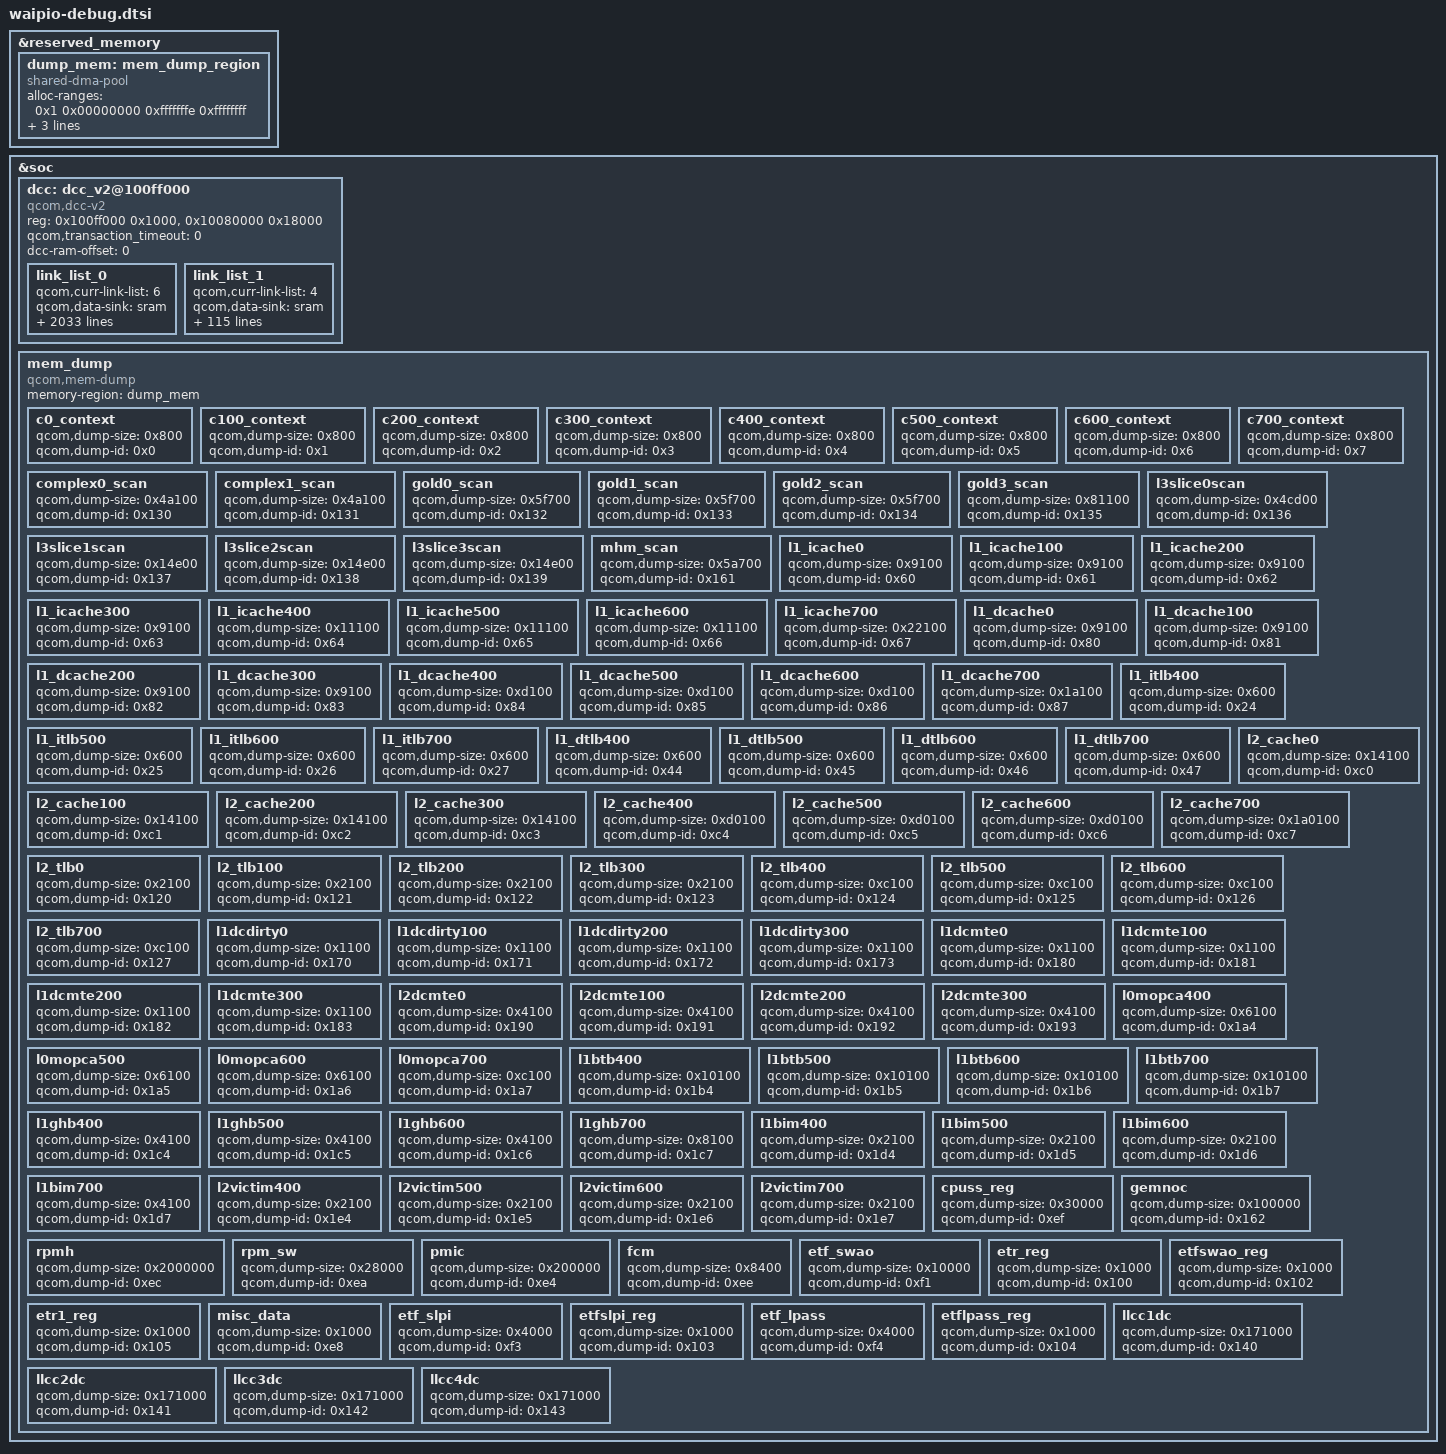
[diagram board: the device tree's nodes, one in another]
#include <dt-bindings/soc/qcom,dcc_v2.h>

&reserved_memory {
	#address-cells = <2>;
	#size-cells = <2>;
	ranges;

	dump_mem: mem_dump_region {
		compatible = "shared-dma-pool";
		alloc-ranges = <0x1 0x00000000 0xfffffffe 0xffffffff>;
		reusable;
		alignment = <0x0 0x400000>;
		size = <0 0x3400000>;
	};
};

&soc {
	dcc: dcc_v2@100ff000 {
		compatible = "qcom,dcc-v2";
		reg = <0x100ff000 0x1000>,
		      <0x10080000 0x18000>;

		qcom,transaction_timeout = <0>;

		reg-names = "dcc-base", "dcc-ram-base";
		dcc-ram-offset = <0>;

		link_list_0 {
			qcom,curr-link-list = <6>;
			qcom,data-sink = "sram";
			qcom,link-list = <DCC_READ 0x1780005c 1 0>,
				<DCC_READ 0x1781005c 1 0>,
				<DCC_READ 0x1782005c 1 0>,
				<DCC_READ 0x1783005c 1 0>,
				<DCC_READ 0x1784005c 1 0>,
				<DCC_READ 0x1785005c 1 0>,
				<DCC_READ 0x1786005c 1 0>,
				<DCC_READ 0x1787005c 1 0>,
				<DCC_READ 0x1740003c 1 0>,
				<DCC_READ 0x17600238 1 0>,
				<DCC_READ 0x17600240 11 0>,
				<DCC_READ 0x17600404 3 0>,
				<DCC_READ 0x1760041c 3 0>,
				<DCC_READ 0x17600434 1 0>,
				<DCC_READ 0x1760043c 1 0>,
				<DCC_READ 0x17600440 1 0>,
				<DCC_READ 0x17400438 1 0>,
				<DCC_READ 0x17600044 1 0>,
				<DCC_READ 0x17600500 1 0>,
				<DCC_READ 0x17600504 5 0>,
				<DCC_READ 0x17900908 1 0>,
				<DCC_READ 0x17900c18 1 0>,
				<DCC_READ 0x17901908 1 0>,
				<DCC_READ 0x17901c18 1 0>,
				<DCC_READ 0x17b90810 1 0>,
				<DCC_READ 0x17b90c50 1 0>,
				<DCC_READ 0x17b90814 1 0>,
				<DCC_READ 0x17b90c54 1 0>,
				<DCC_READ 0x17b90818 1 0>,
				<DCC_READ 0x17b90c58 1 0>,
				<DCC_READ 0x17b93a84 2 0>,
				<DCC_READ 0x17ba0810 1 0>,
				<DCC_READ 0x17ba0c50 1 0>,
				<DCC_READ 0x17ba0814 1 0>,
				<DCC_READ 0x17ba0c54 1 0>,
				<DCC_READ 0x17ba0818 1 0>,
				<DCC_READ 0x17ba0c58 1 0>,
				<DCC_READ 0x17ba3a84 2 0>,
				<DCC_READ 0x17b93500 80 0>,
				<DCC_READ 0x17ba3500 80 0>,
				<DCC_READ 0x17a80000 5 0>,
				<DCC_READ 0x17a8002c 1 0>,
				<DCC_READ 0x17a80038 1 0>,
				<DCC_READ 0x17a82000 5 0>,
				<DCC_READ 0x17a8202c 1 0>,
				<DCC_READ 0x17a82038 1 0>,
				<DCC_READ 0x17a84000 5 0>,
				<DCC_READ 0x17a8402c 1 0>,
				<DCC_READ 0x17a84038 1 0>,
				<DCC_READ 0x17a86000 5 0>,
				<DCC_READ 0x17a8602c 1 0>,
				<DCC_READ 0x17a86038 1 0>,
				<DCC_READ 0x17aa0000 44 0>,
				<DCC_READ 0x17aa00fc 16 0>,
				<DCC_READ 0x17aa0200 2 0>,
				<DCC_READ 0x17aa0300 1 0>,
				<DCC_READ 0x17aa0400 1 0>,
				<DCC_READ 0x17aa0500 1 0>,
				<DCC_READ 0x17aa0600 1 0>,
				<DCC_READ 0x17aa0700 5 0>,
				<DCC_WRITE 0x17a80000 0xf 0>,
				<DCC_READ 0x17a80000 1 0>,
				<DCC_WRITE 0x17a80024 0x0 0>,
				<DCC_READ 0x17a80024 1 0>,
				<DCC_WRITE 0x17a80020 0x0 0>,
				<DCC_READ 0x17a80020 1 0>,
				<DCC_READ 0x17a80038 1 0>,
				<DCC_WRITE 0x17a80020 0x400 0>,
				<DCC_READ 0x17a80020 1 0>,
				<DCC_READ 0x17a80038 1 0>,
				<DCC_WRITE 0x17a80020 0x800 0>,
				<DCC_READ 0x17a80020 1 0>,
				<DCC_READ 0x17a80038 1 0>,
				<DCC_WRITE 0x17a80020 0xc00 0>,
				<DCC_READ 0x17a80020 1 0>,
				<DCC_READ 0x17a80038 1 0>,
				<DCC_WRITE 0x17a80020 0x1000 0>,
				<DCC_READ 0x17a80020 1 0>,
				<DCC_READ 0x17a80038 1 0>,
				<DCC_WRITE 0x17a80020 0x1400 0>,
				<DCC_READ 0x17a80020 1 0>,
				<DCC_READ 0x17a80038 1 0>,
				<DCC_WRITE 0x17a80020 0x1800 0>,
				<DCC_READ 0x17a80020 1 0>,
				<DCC_READ 0x17a80038 1 0>,
				<DCC_WRITE 0x17a80020 0x1c00 0>,
				<DCC_READ 0x17a80020 1 0>,
				<DCC_READ 0x17a80038 1 0>,
				<DCC_WRITE 0x17a80020 0x2000 0>,
				<DCC_READ 0x17a80020 1 0>,
				<DCC_READ 0x17a80038 1 0>,
				<DCC_WRITE 0x17a80020 0x2400 0>,
				<DCC_READ 0x17a80020 1 0>,
				<DCC_READ 0x17a80038 1 0>,
				<DCC_WRITE 0x17a80020 0x2800 0>,
				<DCC_READ 0x17a80020 1 0>,
				<DCC_READ 0x17a80038 1 0>,
				<DCC_WRITE 0x17a80020 0x2c00 0>,
				<DCC_READ 0x17a80020 1 0>,
				<DCC_READ 0x17a80038 1 0>,
				<DCC_WRITE 0x17a80020 0x3000 0>,
				<DCC_READ 0x17a80020 1 0>,
				<DCC_READ 0x17a80038 1 0>,
				<DCC_WRITE 0x17a80020 0x3400 0>,
				<DCC_READ 0x17a80020 1 0>,
				<DCC_READ 0x17a80038 1 0>,
				<DCC_WRITE 0x17a80020 0x3800 0>,
				<DCC_READ 0x17a80020 1 0>,
				<DCC_READ 0x17a80038 1 0>,
				<DCC_WRITE 0x17a80020 0x3c00 0>,
				<DCC_READ 0x17a80020 1 0>,
				<DCC_READ 0x17a80038 1 0>,
				<DCC_WRITE 0x17a80024 0x40000 0>,
				<DCC_READ 0x17a80024 1 0>,
				<DCC_WRITE 0x17a80020 0x0 0>,
				<DCC_READ 0x17a80020 1 0>,
				<DCC_READ 0x17a80038 1 0>,
				<DCC_WRITE 0x17a80020 0x400 0>,
				<DCC_READ 0x17a80020 1 0>,
				<DCC_READ 0x17a80038 1 0>,
				<DCC_WRITE 0x17a80020 0x8000 0>,
				<DCC_READ 0x17a80020 1 0>,
				<DCC_LOOP 32 0 0>,
				<DCC_READ 0x17a80038 1 0>,
				<DCC_LOOP 1 0 0>,
				<DCC_WRITE 0x17a82000 0xf 0>,
				<DCC_READ 0x17a82000 1 0>,
				<DCC_WRITE 0x17a82024 0x0 0>,
				<DCC_READ 0x17a82024 1 0>,
				<DCC_WRITE 0x17a82020 0x0 0>,
				<DCC_READ 0x17a82020 1 0>,
				<DCC_READ 0x17a82038 1 0>,
				<DCC_WRITE 0x17a82020 0x400 0>,
				<DCC_READ 0x17a82020 1 0>,
				<DCC_READ 0x17a82038 1 0>,
				<DCC_WRITE 0x17a82020 0x800 0>,
				<DCC_READ 0x17a82020 1 0>,
				<DCC_READ 0x17a82038 1 0>,
				<DCC_WRITE 0x17a82020 0xc00 0>,
				<DCC_READ 0x17a82020 1 0>,
				<DCC_READ 0x17a82038 1 0>,
				<DCC_WRITE 0x17a82020 0x1000 0>,
				<DCC_READ 0x17a82020 1 0>,
				<DCC_READ 0x17a82038 1 0>,
				<DCC_WRITE 0x17a82020 0x1400 0>,
				<DCC_READ 0x17a82020 1 0>,
				<DCC_READ 0x17a82038 1 0>,
				<DCC_WRITE 0x17a82020 0x1800 0>,
				<DCC_READ 0x17a82020 1 0>,
				<DCC_READ 0x17a82038 1 0>,
				<DCC_WRITE 0x17a82020 0x1c00 0>,
				<DCC_READ 0x17a82020 1 0>,
				<DCC_READ 0x17a82038 1 0>,
				<DCC_WRITE 0x17a82020 0x2000 0>,
				<DCC_READ 0x17a82020 1 0>,
				<DCC_READ 0x17a82038 1 0>,
				<DCC_WRITE 0x17a82020 0x2400 0>,
				<DCC_READ 0x17a82020 1 0>,
				<DCC_READ 0x17a82038 1 0>,
				<DCC_WRITE 0x17a82020 0x2800 0>,
				<DCC_READ 0x17a82020 1 0>,
				<DCC_READ 0x17a82038 1 0>,
				<DCC_WRITE 0x17a82020 0x2c00 0>,
				<DCC_READ 0x17a82020 1 0>,
				<DCC_READ 0x17a82038 1 0>,
				<DCC_WRITE 0x17a82020 0x3000 0>,
				<DCC_READ 0x17a82020 1 0>,
				<DCC_READ 0x17a82038 1 0>,
				<DCC_WRITE 0x17a82020 0x3400 0>,
				<DCC_READ 0x17a82020 1 0>,
				<DCC_READ 0x17a82038 1 0>,
				<DCC_WRITE 0x17a82020 0x3800 0>,
				<DCC_READ 0x17a82020 1 0>,
				<DCC_READ 0x17a82038 1 0>,
				<DCC_WRITE 0x17a82020 0x3c00 0>,
				<DCC_READ 0x17a82020 1 0>,
				<DCC_READ 0x17a82038 1 0>,
				<DCC_WRITE 0x17a82024 0x40000 0>,
				<DCC_READ 0x17a82024 1 0>,
				<DCC_WRITE 0x17a82020 0x0 0>,
				<DCC_READ 0x17a82020 1 0>,
				<DCC_READ 0x17a82038 1 0>,
				<DCC_WRITE 0x17a82020 0x400 0>,
				<DCC_READ 0x17a82020 1 0>,
				<DCC_READ 0x17a82038 1 0>,
				<DCC_WRITE 0x17a82020 0x8000 0>,
				<DCC_READ 0x17a82020 1 0>,
				<DCC_LOOP 32 0 0>,
				<DCC_READ 0x17a82038 1 0>,
				<DCC_LOOP 1 0 0>,
				<DCC_WRITE 0x17a84000 0xf 0>,
				<DCC_READ 0x17a84000 1 0>,
				<DCC_WRITE 0x17a84024 0x0 0>,
				<DCC_READ 0x17a84024 1 0>,
				<DCC_WRITE 0x17a84020 0x0 0>,
				<DCC_READ 0x17a84020 1 0>,
				<DCC_READ 0x17a84038 1 0>,
				<DCC_WRITE 0x17a84020 0x400 0>,
				<DCC_READ 0x17a84020 1 0>,
				<DCC_READ 0x17a84038 1 0>,
				<DCC_WRITE 0x17a84020 0x800 0>,
				<DCC_READ 0x17a84020 1 0>,
				<DCC_READ 0x17a84038 1 0>,
				<DCC_WRITE 0x17a84020 0xc00 0>,
				<DCC_READ 0x17a84020 1 0>,
				<DCC_READ 0x17a84038 1 0>,
				<DCC_WRITE 0x17a84020 0x1000 0>,
				<DCC_READ 0x17a84020 1 0>,
				<DCC_READ 0x17a84038 1 0>,
				<DCC_WRITE 0x17a84020 0x1400 0>,
				<DCC_READ 0x17a84020 1 0>,
				<DCC_READ 0x17a84038 1 0>,
				<DCC_WRITE 0x17a84020 0x1800 0>,
				<DCC_READ 0x17a84020 1 0>,
				<DCC_READ 0x17a84038 1 0>,
				<DCC_WRITE 0x17a84020 0x1c00 0>,
				<DCC_READ 0x17a84020 1 0>,
				<DCC_READ 0x17a84038 1 0>,
				<DCC_WRITE 0x17a84020 0x2000 0>,
				<DCC_READ 0x17a84020 1 0>,
				<DCC_READ 0x17a84038 1 0>,
				<DCC_WRITE 0x17a84020 0x2400 0>,
				<DCC_READ 0x17a84020 1 0>,
				<DCC_READ 0x17a84038 1 0>,
				<DCC_WRITE 0x17a84020 0x2800 0>,
				<DCC_READ 0x17a84020 1 0>,
				<DCC_READ 0x17a84038 1 0>,
				<DCC_WRITE 0x17a84020 0x2c00 0>,
				<DCC_READ 0x17a84020 1 0>,
				<DCC_READ 0x17a84038 1 0>,
				<DCC_WRITE 0x17a84020 0x3000 0>,
				<DCC_READ 0x17a84020 1 0>,
				<DCC_READ 0x17a84038 1 0>,
				<DCC_WRITE 0x17a84020 0x3400 0>,
				<DCC_READ 0x17a84020 1 0>,
				<DCC_READ 0x17a84038 1 0>,
				<DCC_WRITE 0x17a84020 0x3800 0>,
				<DCC_READ 0x17a84020 1 0>,
				<DCC_READ 0x17a84038 1 0>,
				<DCC_WRITE 0x17a84020 0x3c00 0>,
				<DCC_READ 0x17a84020 1 0>,
				<DCC_READ 0x17a84038 1 0>,
				<DCC_WRITE 0x17a84024 0x40000 0>,
				<DCC_READ 0x17a84024 1 0>,
				<DCC_WRITE 0x17a84020 0x0 0>,
				<DCC_READ 0x17a84020 1 0>,
				<DCC_READ 0x17a84038 1 0>,
				<DCC_WRITE 0x17a84020 0x400 0>,
				<DCC_READ 0x17a84020 1 0>,
				<DCC_READ 0x17a84038 1 0>,
				<DCC_WRITE 0x17a84020 0x8000 0>,
				<DCC_READ 0x17a84020 1 0>,
				<DCC_LOOP 32 0 0>,
				<DCC_READ 0x17a84038 1 0>,
				<DCC_LOOP 1 0 0>,
				<DCC_WRITE 0x17a86000 0xf 0>,
				<DCC_READ 0x17a86000 1 0>,
				<DCC_WRITE 0x17a86024 0x0 0>,
				<DCC_READ 0x17a86024 1 0>,
				<DCC_WRITE 0x17a86020 0x0 0>,
				<DCC_READ 0x17a86020 1 0>,
				<DCC_READ 0x17a86038 1 0>,
				<DCC_WRITE 0x17a86020 0x400 0>,
				<DCC_READ 0x17a86020 1 0>,
				<DCC_READ 0x17a86038 1 0>,
				<DCC_WRITE 0x17a86020 0x800 0>,
				<DCC_READ 0x17a86020 1 0>,
				<DCC_READ 0x17a86038 1 0>,
				<DCC_WRITE 0x17a86020 0xc00 0>,
				<DCC_READ 0x17a86020 1 0>,
				<DCC_READ 0x17a86038 1 0>,
				<DCC_WRITE 0x17a86020 0x1000 0>,
				<DCC_READ 0x17a86020 1 0>,
				<DCC_READ 0x17a86038 1 0>,
				<DCC_WRITE 0x17a86020 0x1400 0>,
				<DCC_READ 0x17a86020 1 0>,
				<DCC_READ 0x17a86038 1 0>,
				<DCC_WRITE 0x17a86020 0x1800 0>,
				<DCC_READ 0x17a86020 1 0>,
				<DCC_READ 0x17a86038 1 0>,
				<DCC_WRITE 0x17a86020 0x1c00 0>,
				<DCC_READ 0x17a86020 1 0>,
				<DCC_READ 0x17a86038 1 0>,
				<DCC_WRITE 0x17a86020 0x2000 0>,
				<DCC_READ 0x17a86020 1 0>,
				<DCC_READ 0x17a86038 1 0>,
				<DCC_WRITE 0x17a86020 0x2400 0>,
				<DCC_READ 0x17a86020 1 0>,
				<DCC_READ 0x17a86038 1 0>,
				<DCC_WRITE 0x17a86020 0x2800 0>,
				<DCC_READ 0x17a86020 1 0>,
				<DCC_READ 0x17a86038 1 0>,
				<DCC_WRITE 0x17a86020 0x2c00 0>,
				<DCC_READ 0x17a86020 1 0>,
				<DCC_READ 0x17a86038 1 0>,
				<DCC_WRITE 0x17a86020 0x3000 0>,
				<DCC_READ 0x17a86020 1 0>,
				<DCC_READ 0x17a86038 1 0>,
				<DCC_WRITE 0x17a86020 0x3400 0>,
				<DCC_READ 0x17a86020 1 0>,
				<DCC_READ 0x17a86038 1 0>,
				<DCC_WRITE 0x17a86020 0x3800 0>,
				<DCC_READ 0x17a86020 1 0>,
				<DCC_READ 0x17a86038 1 0>,
				<DCC_WRITE 0x17a86020 0x3c00 0>,
				<DCC_READ 0x17a86020 1 0>,
				<DCC_READ 0x17a86038 1 0>,
				<DCC_WRITE 0x17a86024 0x40000 0>,
				<DCC_READ 0x17a86024 1 0>,
				<DCC_WRITE 0x17a86020 0x0 0>,
				<DCC_READ 0x17a86020 1 0>,
				<DCC_READ 0x17a86038 1 0>,
				<DCC_WRITE 0x17a86020 0x400 0>,
				<DCC_READ 0x17a86020 1 0>,
				<DCC_READ 0x17a86038 1 0>,
				<DCC_WRITE 0x17a86020 0x8000 0>,
				<DCC_READ 0x17a86020 1 0>,
				<DCC_LOOP 32 0 0>,
				<DCC_READ 0x17a86038 1 0>,
				<DCC_LOOP 1 0 0>,
				<DCC_READ 0x0c201244 1 0>,
				<DCC_READ 0x0c202244 1 0>,
				<DCC_READ 0x17b00000 1 0>,
				<DCC_READ 0x17a9208c 1 0>,
				<DCC_WRITE 0x17a9209c 0x78 0>,
				<DCC_WRITE 0x17a9209c 0x0  0>,
				<DCC_WRITE 0x17a92048 0x1  0>,
				<DCC_WRITE 0x17a92090 0x0  0>,
				<DCC_WRITE 0x17a92090 0x25 0>,
				<DCC_READ 0x17a92098 1 0>,
				<DCC_WRITE 0x17a92048 0x1d 0>,
				<DCC_WRITE 0x17a92090 0x0  0>,
				<DCC_WRITE 0x17a92090 0x25 0>,
				<DCC_READ 0x17a92098 1 0>,
				<DCC_READ 0x17a9608c 1 0>,
				<DCC_WRITE 0x17a9609c 0x78 0>,
				<DCC_WRITE 0x17a9609c 0x0  0>,
				<DCC_WRITE 0x17a96048 0x1  0>,
				<DCC_WRITE 0x17a96090 0x0  0>,
				<DCC_WRITE 0x17a96090 0x25 0>,
				<DCC_READ 0x17a96098 1 0>,
				<DCC_WRITE 0x17a96048 0x1d 0>,
				<DCC_WRITE 0x17a96090 0x0  0>,
				<DCC_WRITE 0x17a96090 0x25 0>,
				<DCC_READ 0x17a96098 1 0>,
				<DCC_READ 0x221c21c4 1 0>,
				<DCC_READ 0x01fc8000 1 0>,
				<DCC_READ 0x17400038 1 0>,
				<DCC_READ 0x17d91020 1 0>,
				<DCC_READ 0x17d92020 1 0>,
				<DCC_READ 0x17d93020 1 0>,
				<DCC_READ 0x17d90020 1 0>,
				<DCC_READ 0x17d9134c 1 0>,
				<DCC_READ 0x17d9234c 1 0>,
				<DCC_READ 0x17d9334c 1 0>,
				<DCC_READ 0x17d9034c 1 0>,
				<DCC_READ 0x17d91300 1 0>,
				<DCC_READ 0x17d92300 1 0>,
				<DCC_READ 0x17d93300 1 0>,
				<DCC_READ 0x17d90300 1 0>,
				<DCC_READ 0x19181040 1 0>,
				<DCC_READ 0x19181048 1 0>,
				<DCC_READ 0x19180010 1 0>,
				<DCC_READ 0x19180020 6 0>,
				<DCC_READ 0x19180410 1 0>,
				<DCC_READ 0x19180420 6 0>,
				<DCC_READ 0x19100010 1 0>,
				<DCC_READ 0x19100020 6 0>,
				<DCC_READ 0x19140010 1 0>,
				<DCC_READ 0x19140020 6 0>,
				<DCC_READ 0x19100410 1 0>,
				<DCC_READ 0x19100420 6 0>,
				<DCC_READ 0x19140410 1 0>,
				<DCC_READ 0x19140420 6 0>,
				<DCC_READ 0x19187810 1 0>,
				<DCC_READ 0x19187838 1 0>,
				<DCC_READ 0x19187830 2 0>,
				<DCC_READ 0x19187830 2 0>,
				<DCC_READ 0x19187830 2 0>,
				<DCC_READ 0x19187830 2 0>,
				<DCC_READ 0x19187838 1 0>,
				<DCC_READ 0x19187830 2 0>,
				<DCC_READ 0x19187830 2 0>,
				<DCC_READ 0x19187830 2 0>,
				<DCC_READ 0x19187830 2 0>,
				<DCC_READ 0x19187838 1 0>,
				<DCC_READ 0x19187830 2 0>,
				<DCC_READ 0x19187830 2 0>,
				<DCC_READ 0x19187830 2 0>,
				<DCC_READ 0x19187830 2 0>,
				<DCC_READ 0x19187838 1 0>,
				<DCC_READ 0x19187830 2 0>,
				<DCC_READ 0x19187830 2 0>,
				<DCC_READ 0x19187830 2 0>,
				<DCC_READ 0x19187830 2 0>,
				<DCC_READ 0x19187808 2 0>,
				<DCC_READ 0x19187c10 1 0>,
				<DCC_READ 0x19187c38 1 0>,
				<DCC_READ 0x19187c30 2 0>,
				<DCC_READ 0x19187c30 2 0>,
				<DCC_READ 0x19187c30 2 0>,
				<DCC_READ 0x19187c30 2 0>,
				<DCC_READ 0x19187c38 1 0>,
				<DCC_READ 0x19187c30 2 0>,
				<DCC_READ 0x19187c30 2 0>,
				<DCC_READ 0x19187c30 2 0>,
				<DCC_READ 0x19187c30 2 0>,
				<DCC_READ 0x19187c38 1 0>,
				<DCC_READ 0x19187c30 2 0>,
				<DCC_READ 0x19187c30 2 0>,
				<DCC_READ 0x19187c30 2 0>,
				<DCC_READ 0x19187c30 2 0>,
				<DCC_READ 0x19187c38 1 0>,
				<DCC_READ 0x19187c30 2 0>,
				<DCC_READ 0x19187c30 2 0>,
				<DCC_READ 0x19187c30 2 0>,
				<DCC_READ 0x19187c30 2 0>,
				<DCC_READ 0x19187c08 2 0>,
				<DCC_READ 0x19109010 1 0>,
				<DCC_READ 0x19109038 1 0>,
				<DCC_READ 0x19109030 2 0>,
				<DCC_READ 0x19109030 2 0>,
				<DCC_READ 0x19109030 2 0>,
				<DCC_READ 0x19109030 2 0>,
				<DCC_READ 0x19109038 1 0>,
				<DCC_READ 0x19109030 2 0>,
				<DCC_READ 0x19109030 2 0>,
				<DCC_READ 0x19109030 2 0>,
				<DCC_READ 0x19109030 2 0>,
				<DCC_READ 0x19109038 1 0>,
				<DCC_READ 0x19109030 2 0>,
				<DCC_READ 0x19109030 2 0>,
				<DCC_READ 0x19109030 2 0>,
				<DCC_READ 0x19109030 2 0>,
				<DCC_READ 0x19109038 1 0>,
				<DCC_READ 0x19109030 2 0>,
				<DCC_READ 0x19109030 2 0>,
				<DCC_READ 0x19109030 2 0>,
				<DCC_READ 0x19109030 2 0>,
				<DCC_READ 0x19109008 2 0>,
				<DCC_READ 0x19149010 1 0>,
				<DCC_READ 0x19149038 1 0>,
				<DCC_READ 0x19149030 2 0>,
				<DCC_READ 0x19149030 2 0>,
				<DCC_READ 0x19149030 2 0>,
				<DCC_READ 0x19149030 2 0>,
				<DCC_READ 0x19149038 1 0>,
				<DCC_READ 0x19149030 2 0>,
				<DCC_READ 0x19149030 2 0>,
				<DCC_READ 0x19149030 2 0>,
				<DCC_READ 0x19149030 2 0>,
				<DCC_READ 0x19149038 1 0>,
				<DCC_READ 0x19149030 2 0>,
				<DCC_READ 0x19149030 2 0>,
				<DCC_READ 0x19149030 2 0>,
				<DCC_READ 0x19149030 2 0>,
				<DCC_READ 0x19149038 1 0>,
				<DCC_READ 0x19149030 2 0>,
				<DCC_READ 0x19149030 2 0>,
				<DCC_READ 0x19149030 2 0>,
				<DCC_READ 0x19149030 2 0>,
				<DCC_READ 0x19149008 2 0>,
				<DCC_READ 0x19109410 1 0>,
				<DCC_READ 0x19109438 1 0>,
				<DCC_READ 0x19109430 2 0>,
				<DCC_READ 0x19109430 2 0>,
				<DCC_READ 0x19109430 2 0>,
				<DCC_READ 0x19109430 2 0>,
				<DCC_READ 0x19109438 1 0>,
				<DCC_READ 0x19109430 2 0>,
				<DCC_READ 0x19109430 2 0>,
				<DCC_READ 0x19109430 2 0>,
				<DCC_READ 0x19109430 2 0>,
				<DCC_READ 0x19109438 1 0>,
				<DCC_READ 0x19109430 2 0>,
				<DCC_READ 0x19109430 2 0>,
				<DCC_READ 0x19109430 2 0>,
				<DCC_READ 0x19109430 2 0>,
				<DCC_READ 0x19109438 1 0>,
				<DCC_READ 0x19109430 2 0>,
				<DCC_READ 0x19109430 2 0>,
				<DCC_READ 0x19109430 2 0>,
				<DCC_READ 0x19109430 2 0>,
				<DCC_READ 0x19109408 2 0>,
				<DCC_READ 0x19149410 1 0>,
				<DCC_READ 0x19149438 1 0>,
				<DCC_READ 0x19149430 2 0>,
				<DCC_READ 0x19149430 2 0>,
				<DCC_READ 0x19149430 2 0>,
				<DCC_READ 0x19149430 2 0>,
				<DCC_READ 0x19149438 1 0>,
				<DCC_READ 0x19149430 2 0>,
				<DCC_READ 0x19149430 2 0>,
				<DCC_READ 0x19149430 2 0>,
				<DCC_READ 0x19149430 2 0>,
				<DCC_READ 0x19149438 1 0>,
				<DCC_READ 0x19149430 2 0>,
				<DCC_READ 0x19149430 2 0>,
				<DCC_READ 0x19149430 2 0>,
				<DCC_READ 0x19149430 2 0>,
				<DCC_READ 0x19149438 1 0>,
				<DCC_READ 0x19149430 2 0>,
				<DCC_READ 0x19149430 2 0>,
				<DCC_READ 0x19149430 2 0>,
				<DCC_READ 0x19149430 2 0>,
				<DCC_READ 0x19149408 2 0>,
				<DCC_READ 0x1918f498 1 0>,
				<DCC_READ 0x1918f488 1 0>,
				<DCC_READ 0x1918f490 2 0>,
				<DCC_READ 0x1918f490 2 0>,
				<DCC_READ 0x1918f490 2 0>,
				<DCC_READ 0x1918f490 2 0>,
				<DCC_READ 0x1918f490 2 0>,
				<DCC_READ 0x1918f490 2 0>,
				<DCC_READ 0x1918f490 2 0>,
				<DCC_READ 0x1918f490 2 0>,
				<DCC_READ 0x1918f490 2 0>,
				<DCC_READ 0x1914c098 1 0>,
				<DCC_READ 0x1914c088 1 0>,
				<DCC_READ 0x1914c090 2 0>,
				<DCC_READ 0x1914c090 2 0>,
				<DCC_READ 0x1914c090 2 0>,
				<DCC_READ 0x1914c090 2 0>,
				<DCC_READ 0x1914c090 2 0>,
				<DCC_READ 0x1910c098 1 0>,
				<DCC_READ 0x1910c088 1 0>,
				<DCC_READ 0x1910c090 2 0>,
				<DCC_READ 0x1910c090 2 0>,
				<DCC_READ 0x1910c090 2 0>,
				<DCC_READ 0x1910c090 2 0>,
				<DCC_READ 0x1910c090 2 0>,
				<DCC_READ 0x1918f418 1 0>,
				<DCC_READ 0x1918f408 1 0>,
				<DCC_READ 0x1918f410 2 0>,
				<DCC_READ 0x1918f410 2 0>,
				<DCC_READ 0x1914c018 1 0>,
				<DCC_READ 0x1914c008 1 0>,
				<DCC_READ 0x1914c010 2 0>,
				<DCC_READ 0x1914c010 2 0>,
				<DCC_READ 0x1910c018 1 0>,
				<DCC_READ 0x1910c008 1 0>,
				<DCC_READ 0x1910c010 2 0>,
				<DCC_READ 0x1910c010 2 0>,
				<DCC_READ 0x03d0201c 1 0>,
				<DCC_READ 0x03d00000 1 0>,
				<DCC_READ 0x03d00008 1 0>,
				<DCC_READ 0x03d00044 1 0>,
				<DCC_READ 0x03d00058 1 0>,
				<DCC_READ 0x03d0005c 1 0>,
				<DCC_READ 0x03d00060 1 0>,
				<DCC_READ 0x03d00064 1 0>,
				<DCC_READ 0x03d00068 1 0>,
				<DCC_READ 0x03d0006c 1 0>,
				<DCC_READ 0x03d0007c 1 0>,
				<DCC_READ 0x03d00080 1 0>,
				<DCC_READ 0x03d00084 1 0>,
				<DCC_READ 0x03d00088 1 0>,
				<DCC_READ 0x03d0008c 1 0>,
				<DCC_READ 0x03d00090 1 0>,
				<DCC_READ 0x03d00094 1 0>,
				<DCC_READ 0x03d00098 1 0>,
				<DCC_READ 0x03d0009c 1 0>,
				<DCC_READ 0x03d000a0 1 0>,
				<DCC_READ 0x03d000a4 1 0>,
				<DCC_READ 0x03d000a8 1 0>,
				<DCC_READ 0x03d000ac 1 0>,
				<DCC_READ 0x03d000b0 1 0>,
				<DCC_READ 0x03d000b4 1 0>,
				<DCC_READ 0x03d000b8 1 0>,
				<DCC_READ 0x03d000bc 1 0>,
				<DCC_READ 0x03d000c0 1 0>,
				<DCC_READ 0x03d000c4 1 0>,
				<DCC_READ 0x03d000c8 1 0>,
				<DCC_READ 0x03d000e0 1 0>,
				<DCC_READ 0x03d000e4 1 0>,
				<DCC_READ 0x03d000e8 1 0>,
				<DCC_READ 0x03d000ec 1 0>,
				<DCC_READ 0x03d000f0 1 0>,
				<DCC_READ 0x03d00108 1 0>,
				<DCC_READ 0x03d00110 1 0>,
				<DCC_READ 0x03d0011c 1 0>,
				<DCC_READ 0x03d00124 1 0>,
				<DCC_READ 0x03d00128 1 0>,
				<DCC_READ 0x03d00130 1 0>,
				<DCC_READ 0x03d00140 1 0>,
				<DCC_READ 0x03d00158 1 0>,
				<DCC_READ 0x03d001cc 1 0>,
				<DCC_READ 0x03d001d0 1 0>,
				<DCC_READ 0x03d001d4 1 0>,
				<DCC_READ 0x03d002b4 1 0>,
				<DCC_READ 0x03d002b8 1 0>,
				<DCC_READ 0x03d002c0 1 0>,
				<DCC_READ 0x03d002d0 1 0>,
				<DCC_READ 0x03d002e0 1 0>,
				<DCC_READ 0x03d002f0 1 0>,
				<DCC_READ 0x03d00300 1 0>,
				<DCC_READ 0x03d00310 1 0>,
				<DCC_READ 0x03d00320 1 0>,
				<DCC_READ 0x03d00330 1 0>,
				<DCC_READ 0x03d00340 1 0>,
				<DCC_READ 0x03d00350 1 0>,
				<DCC_READ 0x03d00360 1 0>,
				<DCC_READ 0x03d00370 1 0>,
				<DCC_READ 0x03d00380 1 0>,
				<DCC_READ 0x03d00390 1 0>,
				<DCC_READ 0x03d003a0 1 0>,
				<DCC_READ 0x03d003b0 1 0>,
				<DCC_READ 0x03d003c0 1 0>,
				<DCC_READ 0x03d003d0 1 0>,
				<DCC_READ 0x03d003e0 1 0>,
				<DCC_READ 0x03d00400 1 0>,
				<DCC_READ 0x03d00410 1 0>,
				<DCC_READ 0x03d00414 1 0>,
				<DCC_READ 0x03d00418 1 0>,
				<DCC_READ 0x03d0041c 1 0>,
				<DCC_READ 0x03d00420 1 0>,
				<DCC_READ 0x03d00424 1 0>,
				<DCC_READ 0x03d00428 1 0>,
				<DCC_READ 0x03d0042c 1 0>,
				<DCC_READ 0x03d0043c 1 0>,
				<DCC_READ 0x03d00440 1 0>,
				<DCC_READ 0x03d00444 1 0>,
				<DCC_READ 0x03d00448 1 0>,
				<DCC_READ 0x03d0044c 1 0>,
				<DCC_READ 0x03d00450 1 0>,
				<DCC_READ 0x03d00454 1 0>,
				<DCC_READ 0x03d00458 1 0>,
				<DCC_READ 0x03d0045c 1 0>,
				<DCC_READ 0x03d00460 1 0>,
				<DCC_READ 0x03d00464 1 0>,
				<DCC_READ 0x03d00468 1 0>,
				<DCC_READ 0x03d0046c 1 0>,
				<DCC_READ 0x03d00470 1 0>,
				<DCC_READ 0x03d00474 1 0>,
				<DCC_READ 0x03d004bc 1 0>,
				<DCC_READ 0x03d00800 1 0>,
				<DCC_READ 0x03d00804 1 0>,
				<DCC_READ 0x03d00808 1 0>,
				<DCC_READ 0x03d0080c 1 0>,
				<DCC_READ 0x03d00810 1 0>,
				<DCC_READ 0x03d00814 1 0>,
				<DCC_READ 0x03d00818 1 0>,
				<DCC_READ 0x03d0081c 1 0>,
				<DCC_READ 0x03d00820 1 0>,
				<DCC_READ 0x03d00824 1 0>,
				<DCC_READ 0x03d00828 1 0>,
				<DCC_READ 0x03d0082c 1 0>,
				<DCC_READ 0x03d00830 1 0>,
				<DCC_READ 0x03d00834 1 0>,
				<DCC_READ 0x03d00840 1 0>,
				<DCC_READ 0x03d00844 1 0>,
				<DCC_READ 0x03d00848 1 0>,
				<DCC_READ 0x03d0084c 1 0>,
				<DCC_READ 0x03d00854 1 0>,
				<DCC_READ 0x03d00858 1 0>,
				<DCC_READ 0x03d0085c 1 0>,
				<DCC_READ 0x03d00860 1 0>,
				<DCC_READ 0x03d00864 1 0>,
				<DCC_READ 0x03d00868 1 0>,
				<DCC_READ 0x03d0086c 1 0>,
				<DCC_READ 0x03d00870 1 0>,
				<DCC_READ 0x03d00874 1 0>,
				<DCC_READ 0x03d00878 1 0>,
				<DCC_READ 0x03d0087c 1 0>,
				<DCC_READ 0x03d00880 1 0>,
				<DCC_READ 0x03d00884 1 0>,
				<DCC_READ 0x03d00888 1 0>,
				<DCC_READ 0x03d0088c 1 0>,
				<DCC_READ 0x03d00890 1 0>,
				<DCC_READ 0x03d00894 1 0>,
				<DCC_READ 0x03d00898 1 0>,
				<DCC_READ 0x03d0089c 1 0>,
				<DCC_READ 0x03d008a0 1 0>,
				<DCC_READ 0x03d008a4 1 0>,
				<DCC_READ 0x03d008a8 1 0>,
				<DCC_READ 0x03d008ac 1 0>,
				<DCC_READ 0x03d008b0 1 0>,
				<DCC_READ 0x03d008b4 1 0>,
				<DCC_READ 0x03d008b8 1 0>,
				<DCC_READ 0x03d008bc 1 0>,
				<DCC_READ 0x03d008c0 1 0>,
				<DCC_READ 0x03d008c4 1 0>,
				<DCC_READ 0x03d008c8 1 0>,
				<DCC_READ 0x03d008cc 1 0>,
				<DCC_READ 0x03d008d0 1 0>,
				<DCC_READ 0x03d008d4 1 0>,
				<DCC_READ 0x03d008d8 1 0>,
				<DCC_READ 0x03d008dc 1 0>,
				<DCC_READ 0x03d008e0 1 0>,
				<DCC_READ 0x03d008e4 1 0>,
				<DCC_READ 0x03d008e8 1 0>,
				<DCC_READ 0x03d008ec 1 0>,
				<DCC_READ 0x03d008f0 1 0>,
				<DCC_READ 0x03d008f4 1 0>,
				<DCC_READ 0x03d008f8 1 0>,
				<DCC_READ 0x03d008fc 1 0>,
				<DCC_READ 0x03d00900 1 0>,
				<DCC_READ 0x03d00904 1 0>,
				<DCC_READ 0x03d00908 1 0>,
				<DCC_READ 0x03d0090c 1 0>,
				<DCC_READ 0x03d00980 1 0>,
				<DCC_READ 0x03d00984 1 0>,
				<DCC_READ 0x03d00988 1 0>,
				<DCC_READ 0x03d0098c 1 0>,
				<DCC_READ 0x03d00990 1 0>,
				<DCC_READ 0x03d00994 1 0>,
				<DCC_READ 0x03d00998 1 0>,
				<DCC_READ 0x03d0099c 1 0>,
				<DCC_READ 0x03d009a0 1 0>,
				<DCC_READ 0x03d009c8 1 0>,
				<DCC_READ 0x03d009cc 1 0>,
				<DCC_READ 0x03d009d0 1 0>,
				<DCC_READ 0x03d00a04 1 0>,
				<DCC_READ 0x03d00a08 1 0>,
				<DCC_READ 0x03d00a0c 1 0>,
				<DCC_READ 0x03d00a10 1 0>,
				<DCC_READ 0x03d00a14 1 0>,
				<DCC_READ 0x03d00a18 1 0>,
				<DCC_READ 0x03d00a1c 1 0>,
				<DCC_READ 0x03d00a20 1 0>,
				<DCC_READ 0x03d00a24 1 0>,
				<DCC_READ 0x03d00a28 1 0>,
				<DCC_READ 0x03d00a2c 1 0>,
				<DCC_READ 0x03d00a30 1 0>,
				<DCC_READ 0x03d00a34 1 0>,
				<DCC_READ 0x03d01444 1 0>,
				<DCC_READ 0x03d014d4 1 0>,
				<DCC_READ 0x03d014d8 1 0>,
				<DCC_READ 0x03d017ec 1 0>,
				<DCC_READ 0x03d017f0 1 0>,
				<DCC_READ 0x03d017f4 1 0>,
				<DCC_READ 0x03d017f8 1 0>,
				<DCC_READ 0x03d017fc 1 0>,
				<DCC_READ 0x03d99800 1 0>,
				<DCC_READ 0x03d99804 1 0>,
				<DCC_READ 0x03d99808 1 0>,
				<DCC_READ 0x03d9980c 1 0>,
				<DCC_READ 0x03d99810 1 0>,
				<DCC_READ 0x03d99814 1 0>,
				<DCC_READ 0x03d99818 1 0>,
				<DCC_READ 0x03d9981c 1 0>,
				<DCC_READ 0x03d99828 1 0>,
				<DCC_READ 0x03d9983c 1 0>,
				<DCC_READ 0x03d998ac 1 0>,
				<DCC_READ 0x0018101c 1 0>,
				<DCC_READ 0x00181020 1 0>,
				<DCC_READ 0x03d94000 1 0>,
				<DCC_READ 0x03d94004 1 0>,
				<DCC_READ 0x03d95000 1 0>,
				<DCC_READ 0x03d95004 1 0>,
				<DCC_READ 0x03d95008 1 0>,
				<DCC_READ 0x03d9500c 1 0>,
				<DCC_READ 0x03d96000 1 0>,
				<DCC_READ 0x03d96004 1 0>,
				<DCC_READ 0x03d96008 1 0>,
				<DCC_READ 0x03d9600c 1 0>,
				<DCC_READ 0x03d97000 1 0>,
				<DCC_READ 0x03d97004 1 0>,
				<DCC_READ 0x03d97008 1 0>,
				<DCC_READ 0x03d9700c 1 0>,
				<DCC_READ 0x03d98000 1 0>,
				<DCC_READ 0x03d98004 1 0>,
				<DCC_READ 0x03d98008 1 0>,
				<DCC_READ 0x03d9800c 1 0>,
				<DCC_READ 0x03d99000 1 0>,
				<DCC_READ 0x03d99004 1 0>,
				<DCC_READ 0x03d99008 1 0>,
				<DCC_READ 0x03d9900c 1 0>,
				<DCC_READ 0x03d99010 1 0>,
				<DCC_READ 0x03d99014 1 0>,
				<DCC_READ 0x03d99050 1 0>,
				<DCC_READ 0x03d99054 1 0>,
				<DCC_READ 0x03d99058 1 0>,
				<DCC_READ 0x03d9905c 1 0>,
				<DCC_READ 0x03d99060 1 0>,
				<DCC_READ 0x03d99064 1 0>,
				<DCC_READ 0x03d99068 1 0>,
				<DCC_READ 0x03d9906c 1 0>,
				<DCC_READ 0x03d99070 1 0>,
				<DCC_READ 0x03d99074 1 0>,
				<DCC_READ 0x03d990a8 1 0>,
				<DCC_READ 0x03d990ac 1 0>,
				<DCC_READ 0x03d990b8 1 0>,
				<DCC_READ 0x03d990bc 1 0>,
				<DCC_READ 0x03d990c0 1 0>,
				<DCC_READ 0x03d990c8 1 0>,
				<DCC_READ 0x03d99104 1 0>,
				<DCC_READ 0x03d99108 1 0>,
				<DCC_READ 0x03d9910c 1 0>,
				<DCC_READ 0x03d99110 1 0>,
				<DCC_READ 0x03d99114 1 0>,
				<DCC_READ 0x03d99118 1 0>,
				<DCC_READ 0x03d9911c 1 0>,
				<DCC_READ 0x03d99120 1 0>,
				<DCC_READ 0x03d99130 1 0>,
				<DCC_READ 0x03d99134 1 0>,
				<DCC_READ 0x03d9913c 1 0>,
				<DCC_READ 0x03d99140 1 0>,
				<DCC_READ 0x03d99144 1 0>,
				<DCC_READ 0x03d99148 1 0>,
				<DCC_READ 0x03d9914c 1 0>,
				<DCC_READ 0x03d99150 1 0>,
				<DCC_READ 0x03d99154 1 0>,
				<DCC_READ 0x03d99198 1 0>,
				<DCC_READ 0x03d9919c 1 0>,
				<DCC_READ 0x03d991a0 1 0>,
				<DCC_READ 0x03d991e0 1 0>,
				<DCC_READ 0x03d991e4 1 0>,
				<DCC_READ 0x03d991e8 1 0>,
				<DCC_READ 0x03d99224 1 0>,
				<DCC_READ 0x03d99228 1 0>,
				<DCC_READ 0x03d99280 1 0>,
				<DCC_READ 0x03d99284 1 0>,
				<DCC_READ 0x03d99288 1 0>,
				<DCC_READ 0x03d9928c 1 0>,
				<DCC_READ 0x03d992cc 1 0>,
				<DCC_READ 0x03d992d0 1 0>,
				<DCC_READ 0x03d992d4 1 0>,
				<DCC_READ 0x03d99314 1 0>,
				<DCC_READ 0x03d99318 1 0>,
				<DCC_READ 0x03d9931c 1 0>,
				<DCC_READ 0x03d99358 1 0>,
				<DCC_READ 0x03d9935c 1 0>,
				<DCC_READ 0x03d99360 1 0>,
				<DCC_READ 0x03d993a0 1 0>,
				<DCC_READ 0x03d993a4 1 0>,
				<DCC_READ 0x03d993e4 1 0>,
				<DCC_READ 0x03d993e8 1 0>,
				<DCC_READ 0x03d993ec 1 0>,
				<DCC_READ 0x03d993f0 1 0>,
				<DCC_READ 0x03d9942c 1 0>,
				<DCC_READ 0x03d99430 1 0>,
				<DCC_READ 0x03d99470 1 0>,
				<DCC_READ 0x03d99474 1 0>,
				<DCC_READ 0x03d99478 1 0>,
				<DCC_READ 0x03d99500 1 0>,
				<DCC_READ 0x03d99504 1 0>,
				<DCC_READ 0x03d99508 1 0>,
				<DCC_READ 0x03d9950c 1 0>,
				<DCC_READ 0x03d99528 1 0>,
				<DCC_READ 0x03d9952c 1 0>,
				<DCC_READ 0x03d99530 1 0>,
				<DCC_READ 0x03d99534 1 0>,
				<DCC_READ 0x03d99538 1 0>,
				<DCC_READ 0x03d9953c 1 0>,
				<DCC_READ 0x03d99540 1 0>,
				<DCC_READ 0x03d99544 1 0>,
				<DCC_READ 0x03d99548 1 0>,
				<DCC_READ 0x03d9954c 1 0>,
				<DCC_READ 0x03d99550 1 0>,
				<DCC_READ 0x03d99554 1 0>,
				<DCC_READ 0x03d99558 1 0>,
				<DCC_READ 0x03d9955c 1 0>,
				<DCC_READ 0x03d99560 1 0>,
				<DCC_READ 0x03d99564 1 0>,
				<DCC_READ 0x03d99568 1 0>,
				<DCC_READ 0x03d9956c 1 0>,
				<DCC_READ 0x03d99570 1 0>,
				<DCC_READ 0x03d99574 1 0>,
				<DCC_READ 0x03d99578 1 0>,
				<DCC_READ 0x03d9957c 1 0>,
				<DCC_READ 0x03d99580 1 0>,
				<DCC_READ 0x03d99584 1 0>,
				<DCC_READ 0x03d99588 1 0>,
				<DCC_READ 0x03d9958c 1 0>,
				<DCC_READ 0x03d99590 1 0>,
				<DCC_READ 0x03d99594 1 0>,
				<DCC_READ 0x03d99598 1 0>,
				<DCC_READ 0x03d9959c 1 0>,
				<DCC_READ 0x03d995a0 1 0>,
				<DCC_READ 0x03d995a4 1 0>,
				<DCC_READ 0x03d995a8 1 0>,
				<DCC_READ 0x03d995ac 1 0>,
				<DCC_READ 0x03d995b0 1 0>,
				<DCC_READ 0x03d995b4 1 0>,
				<DCC_READ 0x03d995b8 1 0>,
				<DCC_READ 0x03d995bc 1 0>,
				<DCC_READ 0x03d995c0 1 0>,
				<DCC_READ 0x03d3b000 1 0>,
				<DCC_READ 0x03d3b004 1 0>,
				<DCC_READ 0x03d3b014 1 0>,
				<DCC_READ 0x03d3b01c 1 0>,
				<DCC_READ 0x03d3b028 1 0>,
				<DCC_READ 0x03d3b0ac 1 0>,
				<DCC_READ 0x03d3b100 1 0>,
				<DCC_READ 0x03d3b104 1 0>,
				<DCC_READ 0x03d3b114 1 0>,
				<DCC_READ 0x03d3b11c 1 0>,
				<DCC_READ 0x03d3b128 1 0>,
				<DCC_READ 0x03d3b1ac 1 0>,
				<DCC_READ 0x03d90000 1 0>,
				<DCC_READ 0x03d90004 1 0>,
				<DCC_READ 0x03d90008 1 0>,
				<DCC_READ 0x03d9000c 1 0>,
				<DCC_READ 0x03d90010 1 0>,
				<DCC_READ 0x03d90014 1 0>,
				<DCC_READ 0x03d90018 1 0>,
				<DCC_READ 0x03d9001c 1 0>,
				<DCC_READ 0x03d90020 1 0>,
				<DCC_READ 0x03d90024 1 0>,
				<DCC_READ 0x03d90028 1 0>,
				<DCC_READ 0x03d9002c 1 0>,
				<DCC_READ 0x03d90030 1 0>,
				<DCC_READ 0x03d90034 1 0>,
				<DCC_READ 0x03d90038 1 0>,
				<DCC_READ 0x03d91000 1 0>,
				<DCC_READ 0x03d91004 1 0>,
				<DCC_READ 0x03d91008 1 0>,
				<DCC_READ 0x03d9100c 1 0>,
				<DCC_READ 0x03d91010 1 0>,
				<DCC_READ 0x03d91014 1 0>,
				<DCC_READ 0x03d91018 1 0>,
				<DCC_READ 0x03d9101c 1 0>,
				<DCC_READ 0x03d91020 1 0>,
				<DCC_READ 0x03d91024 1 0>,
				<DCC_READ 0x03d91028 1 0>,
				<DCC_READ 0x03d9102c 1 0>,
				<DCC_READ 0x03d91030 1 0>,
				<DCC_READ 0x03d91034 1 0>,
				<DCC_READ 0x03d91038 1 0>,
				<DCC_READ 0x03d50000 1 0>,
				<DCC_READ 0x03d50004 1 0>,
				<DCC_READ 0x03d50008 1 0>,
				<DCC_READ 0x03d5000c 1 0>,
				<DCC_READ 0x03d50010 1 0>,
				<DCC_READ 0x03d50014 1 0>,
				<DCC_READ 0x03d50018 1 0>,
				<DCC_READ 0x03d5001c 1 0>,
				<DCC_READ 0x03d50020 1 0>,
				<DCC_READ 0x03d50024 1 0>,
				<DCC_READ 0x03d50028 1 0>,
				<DCC_READ 0x03d5002c 1 0>,
				<DCC_READ 0x03d50030 1 0>,
				<DCC_READ 0x03d50034 1 0>,
				<DCC_READ 0x03d50038 1 0>,
				<DCC_READ 0x03d5003c 1 0>,
				<DCC_READ 0x03d50040 1 0>,
				<DCC_READ 0x03d50044 1 0>,
				<DCC_READ 0x03d50048 1 0>,
				<DCC_READ 0x03d5004c 1 0>,
				<DCC_READ 0x03d50050 1 0>,
				<DCC_READ 0x03d500d0 1 0>,
				<DCC_READ 0x03d500d8 1 0>,
				<DCC_READ 0x03d50100 1 0>,
				<DCC_READ 0x03d50104 1 0>,
				<DCC_READ 0x03d50108 1 0>,
				<DCC_READ 0x03d50200 1 0>,
				<DCC_READ 0x03d50204 1 0>,
				<DCC_READ 0x03d50208 1 0>,
				<DCC_READ 0x03d5020c 1 0>,
				<DCC_READ 0x03d50210 1 0>,
				<DCC_READ 0x03d50400 1 0>,
				<DCC_READ 0x03d50404 1 0>,
				<DCC_READ 0x03d50408 1 0>,
				<DCC_READ 0x03d50450 1 0>,
				<DCC_READ 0x03d50460 1 0>,
				<DCC_READ 0x03d50464 1 0>,
				<DCC_READ 0x03d50490 1 0>,
				<DCC_READ 0x03d50494 1 0>,
				<DCC_READ 0x03d50498 1 0>,
				<DCC_READ 0x03d5049c 1 0>,
				<DCC_READ 0x03d504a0 1 0>,
				<DCC_READ 0x03d504a4 1 0>,
				<DCC_READ 0x03d504a8 1 0>,
				<DCC_READ 0x03d504ac 1 0>,
				<DCC_READ 0x03d504b0 1 0>,
				<DCC_READ 0x03d504b4 1 0>,
				<DCC_READ 0x03d504b8 1 0>,
				<DCC_READ 0x03d50500 1 0>,
				<DCC_READ 0x03d50600 1 0>,
				<DCC_READ 0x03d50d00 1 0>,
				<DCC_READ 0x03d50d04 1 0>,
				<DCC_READ 0x03d50d10 1 0>,
				<DCC_READ 0x03d50d14 1 0>,
				<DCC_READ 0x03d50d18 1 0>,
				<DCC_READ 0x03d50d1c 1 0>,
				<DCC_READ 0x03d50d30 1 0>,
				<DCC_READ 0x03d50d34 1 0>,
				<DCC_READ 0x03d50d38 1 0>,
				<DCC_READ 0x03d50d3c 1 0>,
				<DCC_READ 0x03d50d40 1 0>,
				<DCC_READ 0x03d53d44 1 0>,
				<DCC_READ 0x03d53d4c 1 0>,
				<DCC_READ 0x03d53d50 1 0>,
				<DCC_READ 0x03d8e100 1 0>,
				<DCC_READ 0x03d8e104 1 0>,
				<DCC_READ 0x03d8ec00 1 0>,
				<DCC_READ 0x03d8ec04 1 0>,
				<DCC_READ 0x03d8ec0c 1 0>,
				<DCC_READ 0x03d8ec14 1 0>,
				<DCC_READ 0x03d8ec18 1 0>,
				<DCC_READ 0x03d8ec1c 1 0>,
				<DCC_READ 0x03d8ec20 1 0>,
				<DCC_READ 0x03d8ec24 1 0>,
				<DCC_READ 0x03d8ec28 1 0>,
				<DCC_READ 0x03d8ec2c 1 0>,
				<DCC_READ 0x03d8ec30 1 0>,
				<DCC_READ 0x03d8ec34 1 0>,
				<DCC_READ 0x03d8ec38 1 0>,
				<DCC_READ 0x03d8ec40 1 0>,
				<DCC_READ 0x03d8ec44 1 0>,
				<DCC_READ 0x03d8ec48 1 0>,
				<DCC_READ 0x03d8ec4c 1 0>,
				<DCC_READ 0x03d8ec54 1 0>,
				<DCC_READ 0x03d8ec58 1 0>,
				<DCC_READ 0x03d8ec80 1 0>,
				<DCC_READ 0x03d8eca0 1 0>,
				<DCC_READ 0x03d8ecc0 1 0>,
				<DCC_READ 0x03d7d000 1 0>,
				<DCC_READ 0x03d7d004 1 0>,
				<DCC_READ 0x03d7d008 1 0>,
				<DCC_READ 0x03d7d00c 1 0>,
				<DCC_READ 0x03d7d010 1 0>,
				<DCC_READ 0x03d7d014 1 0>,
				<DCC_READ 0x03d7d018 1 0>,
				<DCC_READ 0x03d7d01c 1 0>,
				<DCC_READ 0x03d7d020 1 0>,
				<DCC_READ 0x03d7d024 1 0>,
				<DCC_READ 0x03d7d028 1 0>,
				<DCC_READ 0x03d7d02c 1 0>,
				<DCC_READ 0x03d7d030 1 0>,
				<DCC_READ 0x03d7d034 1 0>,
				<DCC_READ 0x03d7d03c 1 0>,
				<DCC_READ 0x03d7d040 1 0>,
				<DCC_READ 0x03d7d044 1 0>,
				<DCC_READ 0x03d7d400 1 0>,
				<DCC_READ 0x03d7d41c 1 0>,
				<DCC_READ 0x03d7d424 1 0>,
				<DCC_READ 0x03d7d428 1 0>,
				<DCC_READ 0x03d7d42c 1 0>,
				<DCC_READ 0x03d7e000 1 0>,
				<DCC_READ 0x03d7e004 1 0>,
				<DCC_READ 0x03d7e008 1 0>,
				<DCC_READ 0x03d7e00c 1 0>,
				<DCC_READ 0x03d7e010 1 0>,
				<DCC_READ 0x03d7e01c 1 0>,
				<DCC_READ 0x03d7e020 1 0>,
				<DCC_READ 0x03d7e02c 1 0>,
				<DCC_READ 0x03d7e030 1 0>,
				<DCC_READ 0x03d7e03c 1 0>,
				<DCC_READ 0x03d7e044 1 0>,
				<DCC_READ 0x03d7e04c 1 0>,
				<DCC_READ 0x03d7e050 1 0>,
				<DCC_READ 0x03d7e054 1 0>,
				<DCC_READ 0x03d7e058 1 0>,
				<DCC_READ 0x03d7e05c 1 0>,
				<DCC_READ 0x03d7e064 1 0>,
				<DCC_READ 0x03d7e068 1 0>,
				<DCC_READ 0x03d7e06c 1 0>,
				<DCC_READ 0x03d7e070 1 0>,
				<DCC_READ 0x03d7e090 1 0>,
				<DCC_READ 0x03d7e094 1 0>,
				<DCC_READ 0x03d7e098 1 0>,
				<DCC_READ 0x03d7e09c 1 0>,
				<DCC_READ 0x03d7e0a0 1 0>,
				<DCC_READ 0x03d7e0a4 1 0>,
				<DCC_READ 0x03d7e0a8 1 0>,
				<DCC_READ 0x03d7e0b4 1 0>,
				<DCC_READ 0x03d7e0b8 1 0>,
				<DCC_READ 0x03d7e0bc 1 0>,
				<DCC_READ 0x03d7e0c0 1 0>,
				<DCC_READ 0x03d7e100 1 0>,
				<DCC_READ 0x03d7e104 1 0>,
				<DCC_READ 0x03d7e108 1 0>,
				<DCC_READ 0x03d7e10c 1 0>,
				<DCC_READ 0x03d7e110 1 0>,
				<DCC_READ 0x03d7e114 1 0>,
				<DCC_READ 0x03d7e118 1 0>,
				<DCC_READ 0x03d7e11c 1 0>,
				<DCC_READ 0x03d7e120 1 0>,
				<DCC_READ 0x03d7e124 1 0>,
				<DCC_READ 0x03d7e128 1 0>,
				<DCC_READ 0x03d7e12c 1 0>,
				<DCC_READ 0x03d7e130 1 0>,
				<DCC_READ 0x03d7e134 1 0>,
				<DCC_READ 0x03d7e138 1 0>,
				<DCC_READ 0x03d7e13c 1 0>,
				<DCC_READ 0x03d7e140 1 0>,
				<DCC_READ 0x03d7e144 1 0>,
				<DCC_READ 0x03d7e148 1 0>,
				<DCC_READ 0x03d7e14c 1 0>,
				<DCC_READ 0x03d7e180 1 0>,
				<DCC_READ 0x03d7e1c0 1 0>,
				<DCC_READ 0x03d7e1c4 1 0>,
				<DCC_READ 0x03d7e1c8 1 0>,
				<DCC_READ 0x03d7e1cc 1 0>,
				<DCC_READ 0x03d7e1d0 1 0>,
				<DCC_READ 0x03d7e1d4 1 0>,
				<DCC_READ 0x03d7e1d8 1 0>,
				<DCC_READ 0x03d7e1dc 1 0>,
				<DCC_READ 0x03d7e1e0 1 0>,
				<DCC_READ 0x03d7e1e4 1 0>,
				<DCC_READ 0x03d7e1fc 1 0>,
				<DCC_READ 0x03d7e220 1 0>,
				<DCC_READ 0x03d7e224 1 0>,
				<DCC_READ 0x03d7e300 1 0>,
				<DCC_READ 0x03d7e304 1 0>,
				<DCC_READ 0x03d7e30c 1 0>,
				<DCC_READ 0x03d7e310 1 0>,
				<DCC_READ 0x03d7e340 1 0>,
				<DCC_READ 0x03d7e3b0 1 0>,
				<DCC_READ 0x03d7e3c0 1 0>,
				<DCC_READ 0x03d7e3c4 1 0>,
				<DCC_READ 0x03d7e440 1 0>,
				<DCC_READ 0x03d7e444 1 0>,
				<DCC_READ 0x03d7e448 1 0>,
				<DCC_READ 0x03d7e44c 1 0>,
				<DCC_READ 0x03d7e450 1 0>,
				<DCC_READ 0x03d7e480 1 0>,
				<DCC_READ 0x03d7e484 1 0>,
				<DCC_READ 0x03d7e490 1 0>,
				<DCC_READ 0x03d7e494 1 0>,
				<DCC_READ 0x03d7e4a0 1 0>,
				<DCC_READ 0x03d7e4a4 1 0>,
				<DCC_READ 0x03d7e4b0 1 0>,
				<DCC_READ 0x03d7e4b4 1 0>,
				<DCC_READ 0x03d7e500 1 0>,
				<DCC_READ 0x03d7e508 1 0>,
				<DCC_READ 0x03d7e50c 1 0>,
				<DCC_READ 0x03d7e510 1 0>,
				<DCC_READ 0x03d7e520 1 0>,
				<DCC_READ 0x03d7e524 1 0>,
				<DCC_READ 0x03d7e528 1 0>,
				<DCC_READ 0x03d7e53c 1 0>,
				<DCC_READ 0x03d7e540 1 0>,
				<DCC_READ 0x03d7e544 1 0>,
				<DCC_READ 0x03d7e560 1 0>,
				<DCC_READ 0x03d7e564 1 0>,
				<DCC_READ 0x03d7e568 1 0>,
				<DCC_READ 0x03d7e574 1 0>,
				<DCC_READ 0x03d7e588 1 0>,
				<DCC_READ 0x03d7e590 1 0>,
				<DCC_READ 0x03d7e594 1 0>,
				<DCC_READ 0x03d7e598 1 0>,
				<DCC_READ 0x03d7e59c 1 0>,
				<DCC_READ 0x03d7e5a0 1 0>,
				<DCC_READ 0x03d7e5a4 1 0>,
				<DCC_READ 0x03d7e5a8 1 0>,
				<DCC_READ 0x03d7e5ac 1 0>,
				<DCC_READ 0x03d7e5c0 1 0>,
				<DCC_READ 0x03d7e5c4 1 0>,
				<DCC_READ 0x03d7e5c8 1 0>,
				<DCC_READ 0x03d7e5cc 1 0>,
				<DCC_READ 0x03d7e5d0 1 0>,
				<DCC_READ 0x03d7e5d4 1 0>,
				<DCC_READ 0x03d7e5d8 1 0>,
				<DCC_READ 0x03d7e5dc 1 0>,
				<DCC_READ 0x03d7e5e0 1 0>,
				<DCC_READ 0x03d7e5e4 1 0>,
				<DCC_READ 0x03d7e600 1 0>,
				<DCC_READ 0x03d7e604 1 0>,
				<DCC_READ 0x03d7e610 1 0>,
				<DCC_READ 0x03d7e614 1 0>,
				<DCC_READ 0x03d7e618 1 0>,
				<DCC_READ 0x03d7e648 1 0>,
				<DCC_READ 0x03d7e64c 1 0>,
				<DCC_READ 0x03d7e658 1 0>,
				<DCC_READ 0x03d7e65c 1 0>,
				<DCC_READ 0x03d7e660 1 0>,
				<DCC_READ 0x03d7e664 1 0>,
				<DCC_READ 0x03d7e668 1 0>,
				<DCC_READ 0x03d7e66c 1 0>,
				<DCC_READ 0x03d7e670 1 0>,
				<DCC_READ 0x03d7e674 1 0>,
				<DCC_READ 0x03d7e678 1 0>,
				<DCC_READ 0x03d7e700 1 0>,
				<DCC_READ 0x03d7e714 1 0>,
				<DCC_READ 0x03d7e718 1 0>,
				<DCC_READ 0x03d7e71c 1 0>,
				<DCC_READ 0x03d7e720 1 0>,
				<DCC_READ 0x03d7e724 1 0>,
				<DCC_READ 0x03d7e728 1 0>,
				<DCC_READ 0x03d7e72c 1 0>,
				<DCC_READ 0x03d7e730 1 0>,
				<DCC_READ 0x03d7e734 1 0>,
				<DCC_READ 0x03d7e738 1 0>,
				<DCC_READ 0x03d7e73c 1 0>,
				<DCC_READ 0x03d7e740 1 0>,
				<DCC_READ 0x03d7e744 1 0>,
				<DCC_READ 0x03d7e748 1 0>,
				<DCC_READ 0x03d7e74c 1 0>,
				<DCC_READ 0x03d7e750 1 0>,
				<DCC_READ 0x03d7e7c0 1 0>,
				<DCC_READ 0x03d7e7c4 1 0>,
				<DCC_READ 0x03d7e7e0 1 0>,
				<DCC_READ 0x03d7e7e4 1 0>,
				<DCC_READ 0x03d7e7e8 1 0>,
				<DCC_READ 0x17800010 1 0>,
				<DCC_READ 0x17800024 1 0>,
				<DCC_READ 0x17800038 1 0>,
				<DCC_READ 0x1780003c 1 0>,
				<DCC_READ 0x17800040 1 0>,
				<DCC_READ 0x17800044 1 0>,
				<DCC_READ 0x17800048 1 0>,
				<DCC_READ 0x1780004c 1 0>,
				<DCC_READ 0x17800058 1 0>,
				<DCC_READ 0x1780005c 1 0>,
				<DCC_READ 0x17800060 1 0>,
				<DCC_READ 0x17800064 1 0>,
				<DCC_READ 0x1780006c 1 0>,
				<DCC_READ 0x178000f0 1 0>,
				<DCC_READ 0x178000f4 1 0>,
				<DCC_READ 0x178a0204 1 0>,
				<DCC_READ 0x178a0244 1 0>,
				<DCC_READ 0x17e30000 1 0>,
				<DCC_READ 0x17e30008 1 0>,
				<DCC_READ 0x17e30010 1 0>,
				<DCC_READ 0x17e80000 1 0>,
				<DCC_READ 0x17e80008 1 0>,
				<DCC_READ 0x17e80010 1 0>,
				<DCC_READ 0x17f80000 1 0>,
				<DCC_READ 0x17f80008 1 0>,
				<DCC_READ 0x17f80010 1 0>,
				<DCC_READ 0x18080000 1 0>,
				<DCC_READ 0x18080008 1 0>,
				<DCC_READ 0x18080010 1 0>,
				<DCC_READ 0x18180000 1 0>,
				<DCC_READ 0x18180008 1 0>,
				<DCC_READ 0x18180010 1 0>,
				<DCC_READ 0x18280000 1 0>,
				<DCC_READ 0x18280008 1 0>,
				<DCC_READ 0x18280010 1 0>,
				<DCC_READ 0x18380000 1 0>,
				<DCC_READ 0x18380008 1 0>,
				<DCC_READ 0x18380010 1 0>,
				<DCC_READ 0x18480000 1 0>,
				<DCC_READ 0x18480008 1 0>,
				<DCC_READ 0x18480010 1 0>,
				<DCC_READ 0x18580000 1 0>,
				<DCC_READ 0x18580008 1 0>,
				<DCC_READ 0x18580010 1 0>,
				<DCC_READ 0x17810010 1 0>,
				<DCC_READ 0x17810024 1 0>,
				<DCC_READ 0x17810038 1 0>,
				<DCC_READ 0x1781003c 1 0>,
				<DCC_READ 0x17810040 1 0>,
				<DCC_READ 0x17810044 1 0>,
				<DCC_READ 0x17810048 1 0>,
				<DCC_READ 0x1781004c 1 0>,
				<DCC_READ 0x17810058 1 0>,
				<DCC_READ 0x1781005c 1 0>,
				<DCC_READ 0x17810060 1 0>,
				<DCC_READ 0x17810064 1 0>,
				<DCC_READ 0x1781006c 1 0>,
				<DCC_READ 0x178100f0 1 0>,
				<DCC_READ 0x178100f4 1 0>,
				<DCC_READ 0x17820010 1 0>,
				<DCC_READ 0x17820024 1 0>,
				<DCC_READ 0x17820038 1 0>,
				<DCC_READ 0x1782003c 1 0>,
				<DCC_READ 0x17820040 1 0>,
				<DCC_READ 0x17820044 1 0>,
				<DCC_READ 0x17820048 1 0>,
				<DCC_READ 0x1782004c 1 0>,
				<DCC_READ 0x17820058 1 0>,
				<DCC_READ 0x1782005c 1 0>,
				<DCC_READ 0x17820060 1 0>,
				<DCC_READ 0x17820064 1 0>,
				<DCC_READ 0x178200f0 1 0>,
				<DCC_READ 0x178200f4 1 0>,
				<DCC_READ 0x17830010 1 0>,
				<DCC_READ 0x17830024 1 0>,
				<DCC_READ 0x17830038 1 0>,
				<DCC_READ 0x1783003c 1 0>,
				<DCC_READ 0x17830040 1 0>,
				<DCC_READ 0x17830044 1 0>,
				<DCC_READ 0x17830048 1 0>,
				<DCC_READ 0x1783004c 1 0>,
				<DCC_READ 0x17830058 1 0>,
				<DCC_READ 0x1783005c 1 0>,
				<DCC_READ 0x17830060 1 0>,
				<DCC_READ 0x17830064 1 0>,
				<DCC_READ 0x178300f0 1 0>,
				<DCC_READ 0x178300f4 1 0>,
				<DCC_READ 0x17840010 1 0>,
				<DCC_READ 0x17840024 1 0>,
				<DCC_READ 0x17840038 1 0>,
				<DCC_READ 0x1784003c 1 0>,
				<DCC_READ 0x17840040 1 0>,
				<DCC_READ 0x17840044 1 0>,
				<DCC_READ 0x17840048 1 0>,
				<DCC_READ 0x1784004c 1 0>,
				<DCC_READ 0x17840058 1 0>,
				<DCC_READ 0x1784005c 1 0>,
				<DCC_READ 0x17840060 1 0>,
				<DCC_READ 0x17840064 1 0>,
				<DCC_READ 0x178400f0 1 0>,
				<DCC_READ 0x178400f4 1 0>,
				<DCC_READ 0x17850010 1 0>,
				<DCC_READ 0x17850024 1 0>,
				<DCC_READ 0x17850038 1 0>,
				<DCC_READ 0x1785003c 1 0>,
				<DCC_READ 0x17850040 1 0>,
				<DCC_READ 0x17850044 1 0>,
				<DCC_READ 0x17850048 1 0>,
				<DCC_READ 0x1785004c 1 0>,
				<DCC_READ 0x17850058 1 0>,
				<DCC_READ 0x1785005c 1 0>,
				<DCC_READ 0x17850060 1 0>,
				<DCC_READ 0x17850064 1 0>,
				<DCC_READ 0x178500f0 1 0>,
				<DCC_READ 0x178500f4 1 0>,
				<DCC_READ 0x17860010 1 0>,
				<DCC_READ 0x17860024 1 0>,
				<DCC_READ 0x17860038 1 0>,
				<DCC_READ 0x1786003c 1 0>,
				<DCC_READ 0x17860040 1 0>,
				<DCC_READ 0x17860044 1 0>,
				<DCC_READ 0x17860048 1 0>,
				<DCC_READ 0x1786004c 1 0>,
				<DCC_READ 0x17860058 1 0>,
				<DCC_READ 0x1786005c 1 0>,
				<DCC_READ 0x17860060 1 0>,
				<DCC_READ 0x17860064 1 0>,
				<DCC_READ 0x178600f0 1 0>,
				<DCC_READ 0x178600f4 1 0>,
				<DCC_READ 0x17870010 1 0>,
				<DCC_READ 0x17870024 1 0>,
				<DCC_READ 0x17870038 1 0>,
				<DCC_READ 0x1787003c 1 0>,
				<DCC_READ 0x17870040 1 0>,
				<DCC_READ 0x17870044 1 0>,
				<DCC_READ 0x17870048 1 0>,
				<DCC_READ 0x1787004c 1 0>,
				<DCC_READ 0x17870058 1 0>,
				<DCC_READ 0x1787005c 1 0>,
				<DCC_READ 0x17870060 1 0>,
				<DCC_READ 0x17870064 1 0>,
				<DCC_READ 0x178700f0 1 0>,
				<DCC_READ 0x178700f4 1 0>,
				<DCC_READ 0x178a0010 1 0>,
				<DCC_READ 0x178a0024 1 0>,
				<DCC_READ 0x178a0038 1 0>,
				<DCC_READ 0x178a003c 1 0>,
				<DCC_READ 0x178a0040 1 0>,
				<DCC_READ 0x178a0044 1 0>,
				<DCC_READ 0x178a0048 1 0>,
				<DCC_READ 0x178a004c 1 0>,
				<DCC_READ 0x178a006c 1 0>,
				<DCC_READ 0x178a0070 1 0>,
				<DCC_READ 0x178a0074 1 0>,
				<DCC_READ 0x178a0078 1 0>,
				<DCC_READ 0x178a007c 1 0>,
				<DCC_READ 0x178a0084 1 0>,
				<DCC_READ 0x178a00f4 1 0>,
				<DCC_READ 0x178a00f8 1 0>,
				<DCC_READ 0x178a00fc 1 0>,
				<DCC_READ 0x178a0100 1 0>,
				<DCC_READ 0x178a0104 1 0>,
				<DCC_READ 0x178a0118 1 0>,
				<DCC_READ 0x178a011c 1 0>,
				<DCC_READ 0x178a0120 1 0>,
				<DCC_READ 0x178a0124 1 0>,
				<DCC_READ 0x178a0128 1 0>,
				<DCC_READ 0x178a012c 1 0>,
				<DCC_READ 0x178a0130 1 0>,
				<DCC_READ 0x178a0134 1 0>,
				<DCC_READ 0x178a0138 1 0>,
				<DCC_READ 0x178a0158 1 0>,
				<DCC_READ 0x178a015c 1 0>,
				<DCC_READ 0x178a0160 1 0>,
				<DCC_READ 0x178a0164 1 0>,
				<DCC_READ 0x178a0168 1 0>,
				<DCC_READ 0x178a0170 1 0>,
				<DCC_READ 0x178a0174 1 0>,
				<DCC_READ 0x178a0188 1 0>,
				<DCC_READ 0x178a018c 1 0>,
				<DCC_READ 0x178a0190 1 0>,
				<DCC_READ 0x178a0194 1 0>,
				<DCC_READ 0x178a0198 1 0>,
				<DCC_READ 0x178a01ac 1 0>,
				<DCC_READ 0x178a01b0 1 0>,
				<DCC_READ 0x178a01b4 1 0>,
				<DCC_READ 0x178a01b8 1 0>,
				<DCC_READ 0x178a01bc 1 0>,
				<DCC_READ 0x178a01c0 1 0>,
				<DCC_READ 0x178a01c8 1 0>,
				<DCC_READ 0x17880010 1 0>,
				<DCC_READ 0x17880024 1 0>,
				<DCC_READ 0x17880038 1 0>,
				<DCC_READ 0x1788003c 1 0>,
				<DCC_READ 0x17880040 1 0>,
				<DCC_READ 0x17880044 1 0>,
				<DCC_READ 0x17880048 1 0>,
				<DCC_READ 0x1788004c 1 0>,
				<DCC_READ 0x17890010 1 0>,
				<DCC_READ 0x17890024 1 0>,
				<DCC_READ 0x17890038 1 0>,
				<DCC_READ 0x1789003c 1 0>,
				<DCC_READ 0x17890040 1 0>,
				<DCC_READ 0x17890044 1 0>,
				<DCC_READ 0x17890048 1 0>,
				<DCC_READ 0x1789004c 1 0>,
				<DCC_READ 0x1908005c 1 0>,
				<DCC_READ 0x190800c8 1 0>,
				<DCC_READ 0x190800d4 1 0>,
				<DCC_READ 0x190800e0 1 0>,
				<DCC_READ 0x190800ec 1 0>,
				<DCC_READ 0x190800f8 1 0>,
				<DCC_READ 0x190801b4 1 0>,
				<DCC_READ 0x190a80f8 1 0>,
				<DCC_READ 0x190a80fc 1 0>,
				<DCC_READ 0x190a8100 1 0>,
				<DCC_READ 0x190a8104 1 0>,
				<DCC_READ 0x190a8108 1 0>,
				<DCC_READ 0x190a810c 1 0>,
				<DCC_READ 0x190a8110 1 0>,
				<DCC_READ 0x190a816c 1 0>,
				<DCC_READ 0x190a8170 1 0>,
				<DCC_READ 0x190a8174 1 0>,
				<DCC_READ 0x190a8178 1 0>,
				<DCC_READ 0x190a818c 1 0>,
				<DCC_READ 0x190a8190 1 0>,
				<DCC_READ 0x190a8194 1 0>,
				<DCC_READ 0x190a8198 1 0>,
				<DCC_READ 0x190a819c 1 0>,
				<DCC_READ 0x190a81a0 1 0>,
				<DCC_READ 0x190a81c8 1 0>,
				<DCC_READ 0x190a81f8 1 0>,
				<DCC_READ 0x190a84c4 1 0>,
				<DCC_READ 0x190a8804 1 0>,
				<DCC_READ 0x190a880c 1 0>,
				<DCC_READ 0x190a8860 1 0>,
				<DCC_READ 0x190a8864 1 0>,
				<DCC_READ 0x190a8868 1 0>,
				<DCC_READ 0x190a9188 1 0>,
				<DCC_READ 0x190a918c 1 0>,
				<DCC_READ 0x190a9190 1 0>,
				<DCC_READ 0x190a9194 1 0>,
				<DCC_READ 0x190a9198 1 0>,
				<DCC_READ 0x190a919c 1 0>,
				<DCC_READ 0x190a91a0 1 0>,
				<DCC_READ 0x190a91a4 1 0>,
				<DCC_READ 0x190a91c8 1 0>,
				<DCC_READ 0x190aa044 1 0>,
				<DCC_READ 0x19220348 1 0>,
				<DCC_READ 0x19220480 1 0>,
				<DCC_READ 0x19222400 1 0>,
				<DCC_READ 0x19223220 1 0>,
				<DCC_READ 0x19223224 1 0>,
				<DCC_READ 0x19223228 1 0>,
				<DCC_READ 0x1922322c 1 0>,
				<DCC_READ 0x19223308 1 0>,
				<DCC_READ 0x19223318 1 0>,
				<DCC_READ 0x19238100 1 0>,
				<DCC_READ 0x19242044 1 0>,
				<DCC_READ 0x19242048 1 0>,
				<DCC_READ 0x1924204c 1 0>,
				<DCC_READ 0x192420b0 1 0>,
				<DCC_READ 0x19242104 1 0>,
				<DCC_READ 0x19242114 1 0>,
				<DCC_READ 0x19248004 1 0>,
				<DCC_READ 0x19248008 1 0>,
				<DCC_READ 0x1924800c 1 0>,
				<DCC_READ 0x19248010 1 0>,
				<DCC_READ 0x1924c030 1 0>,
				<DCC_READ 0x19250020 1 0>,
				<DCC_READ 0x19252028 1 0>,
				<DCC_READ 0x1926004c 1 0>,
				<DCC_READ 0x19260050 1 0>,
				<DCC_READ 0x19260054 1 0>,
				<DCC_READ 0x19260058 1 0>,
				<DCC_READ 0x1926005c 1 0>,
				<DCC_READ 0x19260060 1 0>,
				<DCC_READ 0x19260064 1 0>,
				<DCC_READ 0x19260068 1 0>,
				<DCC_READ 0x19320348 1 0>,
				<DCC_READ 0x19320480 1 0>,
				<DCC_READ 0x19322400 1 0>,
				<DCC_READ 0x19323220 1 0>,
				<DCC_READ 0x19323224 1 0>,
				<DCC_READ 0x19323228 1 0>,
				<DCC_READ 0x1932322c 1 0>,
				<DCC_READ 0x19323308 1 0>,
				<DCC_READ 0x19323318 1 0>,
				<DCC_READ 0x19338100 1 0>,
				<DCC_READ 0x19342044 1 0>,
				<DCC_READ 0x19342048 1 0>,
				<DCC_READ 0x1934204c 1 0>,
				<DCC_READ 0x193420b0 1 0>,
				<DCC_READ 0x19342104 1 0>,
				<DCC_READ 0x19342114 1 0>,
				<DCC_READ 0x19348004 1 0>,
				<DCC_READ 0x19348008 1 0>,
				<DCC_READ 0x1934800c 1 0>,
				<DCC_READ 0x19348010 1 0>,
				<DCC_READ 0x1934c030 1 0>,
				<DCC_READ 0x19350020 1 0>,
				<DCC_READ 0x19352028 1 0>,
				<DCC_READ 0x1936004c 1 0>,
				<DCC_READ 0x19360050 1 0>,
				<DCC_READ 0x19360054 1 0>,
				<DCC_READ 0x19360058 1 0>,
				<DCC_READ 0x1936005c 1 0>,
				<DCC_READ 0x19360060 1 0>,
				<DCC_READ 0x19360064 1 0>,
				<DCC_READ 0x19360068 1 0>,
				<DCC_READ 0x19620348 1 0>,
				<DCC_READ 0x19620480 1 0>,
				<DCC_READ 0x19622400 1 0>,
				<DCC_READ 0x19623220 1 0>,
				<DCC_READ 0x19623224 1 0>,
				<DCC_READ 0x19623228 1 0>,
				<DCC_READ 0x1962322c 1 0>,
				<DCC_READ 0x19623308 1 0>,
				<DCC_READ 0x19623318 1 0>,
				<DCC_READ 0x19638100 1 0>,
				<DCC_READ 0x19642044 1 0>,
				<DCC_READ 0x19642048 1 0>,
				<DCC_READ 0x1964204c 1 0>,
				<DCC_READ 0x196420b0 1 0>,
				<DCC_READ 0x19642104 1 0>,
				<DCC_READ 0x19642114 1 0>,
				<DCC_READ 0x19648004 1 0>,
				<DCC_READ 0x19648008 1 0>,
				<DCC_READ 0x1964800c 1 0>,
				<DCC_READ 0x19648010 1 0>,
				<DCC_READ 0x1964c030 1 0>,
				<DCC_READ 0x19650020 1 0>,
				<DCC_READ 0x19652028 1 0>,
				<DCC_READ 0x1966004c 1 0>,
				<DCC_READ 0x19660050 1 0>,
				<DCC_READ 0x19660054 1 0>,
				<DCC_READ 0x19660058 1 0>,
				<DCC_READ 0x1966005c 1 0>,
				<DCC_READ 0x19660060 1 0>,
				<DCC_READ 0x19660064 1 0>,
				<DCC_READ 0x19660068 1 0>,
				<DCC_READ 0x19720348 1 0>,
				<DCC_READ 0x19720480 1 0>,
				<DCC_READ 0x19722400 1 0>,
				<DCC_READ 0x19723220 1 0>,
				<DCC_READ 0x19723224 1 0>,
				<DCC_READ 0x19723228 1 0>,
				<DCC_READ 0x1972322c 1 0>,
				<DCC_READ 0x19723308 1 0>,
				<DCC_READ 0x19723318 1 0>,
				<DCC_READ 0x19738100 1 0>,
				<DCC_READ 0x19742044 1 0>,
				<DCC_READ 0x19742048 1 0>,
				<DCC_READ 0x1974204c 1 0>,
				<DCC_READ 0x197420b0 1 0>,
				<DCC_READ 0x19742104 1 0>,
				<DCC_READ 0x19742114 1 0>,
				<DCC_READ 0x19748004 1 0>,
				<DCC_READ 0x19748008 1 0>,
				<DCC_READ 0x1974800c 1 0>,
				<DCC_READ 0x19748010 1 0>,
				<DCC_READ 0x1974c030 1 0>,
				<DCC_READ 0x19750020 1 0>,
				<DCC_READ 0x19752028 1 0>,
				<DCC_READ 0x1976004c 1 0>,
				<DCC_READ 0x19760050 1 0>,
				<DCC_READ 0x19760054 1 0>,
				<DCC_READ 0x19760058 1 0>,
				<DCC_READ 0x1976005c 1 0>,
				<DCC_READ 0x19760060 1 0>,
				<DCC_READ 0x19760064 1 0>,
				<DCC_READ 0x19760068 1 0>,
				<DCC_READ 0x1925802c 1 0>,
				<DCC_READ 0x1925809c 1 0>,
				<DCC_READ 0x192580a0 1 0>,
				<DCC_READ 0x192580a8 1 0>,
				<DCC_READ 0x192580ac 1 0>,
				<DCC_READ 0x192580b0 1 0>,
				<DCC_READ 0x192580b8 1 0>,
				<DCC_READ 0x192580c0 1 0>,
				<DCC_READ 0x192580c4 1 0>,
				<DCC_READ 0x192580c8 1 0>,
				<DCC_READ 0x192580cc 1 0>,
				<DCC_READ 0x192580d0 1 0>,
				<DCC_READ 0x192580d4 1 0>,
				<DCC_READ 0x192580d8 1 0>,
				<DCC_READ 0x192580e0 1 0>,
				<DCC_READ 0x192580e8 1 0>,
				<DCC_READ 0x192580f0 1 0>,
				<DCC_READ 0x192580f8 1 0>,
				<DCC_READ 0x19258100 1 0>,
				<DCC_READ 0x19258108 1 0>,
				<DCC_READ 0x19258110 1 0>,
				<DCC_READ 0x19258118 1 0>,
				<DCC_READ 0x19258120 1 0>,
				<DCC_READ 0x19258128 1 0>,
				<DCC_READ 0x19258210 1 0>,
				<DCC_READ 0x19258214 1 0>,
				<DCC_READ 0x19258218 1 0>,
				<DCC_READ 0x19259010 1 0>,
				<DCC_READ 0x19259070 1 0>,
				<DCC_READ 0x1925b004 1 0>,
				<DCC_READ 0x1965802c 1 0>,
				<DCC_READ 0x1965809c 1 0>,
				<DCC_READ 0x196580a0 1 0>,
				<DCC_READ 0x196580a8 1 0>,
				<DCC_READ 0x196580ac 1 0>,
				<DCC_READ 0x196580b0 1 0>,
				<DCC_READ 0x196580b8 1 0>,
				<DCC_READ 0x196580c0 1 0>,
				<DCC_READ 0x196580c4 1 0>,
				<DCC_READ 0x196580c8 1 0>,
				<DCC_READ 0x196580cc 1 0>,
				<DCC_READ 0x196580d0 1 0>,
				<DCC_READ 0x196580d4 1 0>,
				<DCC_READ 0x196580d8 1 0>,
				<DCC_READ 0x196580e0 1 0>,
				<DCC_READ 0x196580e8 1 0>,
				<DCC_READ 0x196580f0 1 0>,
				<DCC_READ 0x196580f8 1 0>,
				<DCC_READ 0x19658100 1 0>,
				<DCC_READ 0x19658108 1 0>,
				<DCC_READ 0x19658110 1 0>,
				<DCC_READ 0x19658118 1 0>,
				<DCC_READ 0x19658120 1 0>,
				<DCC_READ 0x19658128 1 0>,
				<DCC_READ 0x19658210 1 0>,
				<DCC_READ 0x19658214 1 0>,
				<DCC_READ 0x19658218 1 0>,
				<DCC_READ 0x19659010 1 0>,
				<DCC_READ 0x19659070 1 0>,
				<DCC_READ 0x1965b004 1 0>,
				<DCC_READ 0x1935802c 1 0>,
				<DCC_READ 0x1935809c 1 0>,
				<DCC_READ 0x193580a0 1 0>,
				<DCC_READ 0x193580a8 1 0>,
				<DCC_READ 0x193580ac 1 0>,
				<DCC_READ 0x193580b0 1 0>,
				<DCC_READ 0x193580b8 1 0>,
				<DCC_READ 0x193580c0 1 0>,
				<DCC_READ 0x193580c4 1 0>,
				<DCC_READ 0x193580c8 1 0>,
				<DCC_READ 0x193580cc 1 0>,
				<DCC_READ 0x193580d0 1 0>,
				<DCC_READ 0x193580d4 1 0>,
				<DCC_READ 0x193580d8 1 0>,
				<DCC_READ 0x193580e0 1 0>,
				<DCC_READ 0x193580e8 1 0>,
				<DCC_READ 0x193580f0 1 0>,
				<DCC_READ 0x193580f8 1 0>,
				<DCC_READ 0x19358100 1 0>,
				<DCC_READ 0x19358108 1 0>,
				<DCC_READ 0x19358110 1 0>,
				<DCC_READ 0x19358118 1 0>,
				<DCC_READ 0x19358120 1 0>,
				<DCC_READ 0x19358128 1 0>,
				<DCC_READ 0x19358210 1 0>,
				<DCC_READ 0x19358214 1 0>,
				<DCC_READ 0x19358218 1 0>,
				<DCC_READ 0x19359010 1 0>,
				<DCC_READ 0x19359070 1 0>,
				<DCC_READ 0x1935b004 1 0>,
				<DCC_READ 0x1975802c 1 0>,
				<DCC_READ 0x1975809c 1 0>,
				<DCC_READ 0x197580a0 1 0>,
				<DCC_READ 0x197580a8 1 0>,
				<DCC_READ 0x197580ac 1 0>,
				<DCC_READ 0x197580b0 1 0>,
				<DCC_READ 0x197580b8 1 0>,
				<DCC_READ 0x197580c0 1 0>,
				<DCC_READ 0x197580c4 1 0>,
				<DCC_READ 0x197580c8 1 0>,
				<DCC_READ 0x197580cc 1 0>,
				<DCC_READ 0x197580d0 1 0>,
				<DCC_READ 0x197580d4 1 0>,
				<DCC_READ 0x197580d8 1 0>,
				<DCC_READ 0x197580e0 1 0>,
				<DCC_READ 0x197580e8 1 0>,
				<DCC_READ 0x197580f0 1 0>,
				<DCC_READ 0x197580f8 1 0>,
				<DCC_READ 0x19758100 1 0>,
				<DCC_READ 0x19758108 1 0>,
				<DCC_READ 0x19758110 1 0>,
				<DCC_READ 0x19758118 1 0>,
				<DCC_READ 0x19758120 1 0>,
				<DCC_READ 0x19758128 1 0>,
				<DCC_READ 0x19758210 1 0>,
				<DCC_READ 0x19758214 1 0>,
				<DCC_READ 0x19758218 1 0>,
				<DCC_READ 0x19759010 1 0>,
				<DCC_READ 0x19759070 1 0>,
				<DCC_READ 0x1975b004 1 0>,
				<DCC_READ 0x192c0310 1 0>,
				<DCC_READ 0x192c0400 1 0>,
				<DCC_READ 0x192c0404 1 0>,
				<DCC_READ 0x192c0410 1 0>,
				<DCC_READ 0x192c0414 1 0>,
				<DCC_READ 0x192c0418 1 0>,
				<DCC_READ 0x192c0420 1 0>,
				<DCC_READ 0x192c0424 1 0>,
				<DCC_READ 0x192c0430 1 0>,
				<DCC_READ 0x192c0440 1 0>,
				<DCC_READ 0x192c0448 1 0>,
				<DCC_READ 0x192c04a0 1 0>,
				<DCC_READ 0x192c04b0 1 0>,
				<DCC_READ 0x192c04b4 1 0>,
				<DCC_READ 0x192c04b8 1 0>,
				<DCC_READ 0x192c04d0 1 0>,
				<DCC_READ 0x192c04d4 1 0>,
				<DCC_READ 0x192c341c 1 0>,
				<DCC_READ 0x192c5804 1 0>,
				<DCC_READ 0x192c590c 1 0>,
				<DCC_READ 0x192c5a14 1 0>,
				<DCC_READ 0x192c5c1c 1 0>,
				<DCC_READ 0x192c5c38 1 0>,
				<DCC_READ 0x192c9100 1 0>,
				<DCC_READ 0x192c9110 1 0>,
				<DCC_READ 0x192c9120 1 0>,
				<DCC_READ 0x192c9180 1 0>,
				<DCC_READ 0x192c9184 1 0>,
				<DCC_READ 0x193c0310 1 0>,
				<DCC_READ 0x193c0400 1 0>,
				<DCC_READ 0x193c0404 1 0>,
				<DCC_READ 0x193c0410 1 0>,
				<DCC_READ 0x193c0414 1 0>,
				<DCC_READ 0x193c0418 1 0>,
				<DCC_READ 0x193c0420 1 0>,
				<DCC_READ 0x193c0424 1 0>,
				<DCC_READ 0x193c0430 1 0>,
				<DCC_READ 0x193c0440 1 0>,
				<DCC_READ 0x193c0448 1 0>,
				<DCC_READ 0x193c04a0 1 0>,
				<DCC_READ 0x193c04b0 1 0>,
				<DCC_READ 0x193c04b4 1 0>,
				<DCC_READ 0x193c04b8 1 0>,
				<DCC_READ 0x193c04d0 1 0>,
				<DCC_READ 0x193c04d4 1 0>,
				<DCC_READ 0x193c341c 1 0>,
				<DCC_READ 0x193c5804 1 0>,
				<DCC_READ 0x193c590c 1 0>,
				<DCC_READ 0x193c5a14 1 0>,
				<DCC_READ 0x193c5c1c 1 0>,
				<DCC_READ 0x193c5c38 1 0>,
				<DCC_READ 0x193c9100 1 0>,
				<DCC_READ 0x193c9110 1 0>,
				<DCC_READ 0x193c9120 1 0>,
				<DCC_READ 0x193c9180 1 0>,
				<DCC_READ 0x193c9184 1 0>,
				<DCC_READ 0x196c0310 1 0>,
				<DCC_READ 0x196c0400 1 0>,
				<DCC_READ 0x196c0404 1 0>,
				<DCC_READ 0x196c0410 1 0>,
				<DCC_READ 0x196c0414 1 0>,
				<DCC_READ 0x196c0418 1 0>,
				<DCC_READ 0x196c0420 1 0>,
				<DCC_READ 0x196c0424 1 0>,
				<DCC_READ 0x196c0430 1 0>,
				<DCC_READ 0x196c0440 1 0>,
				<DCC_READ 0x196c0448 1 0>,
				<DCC_READ 0x196c04a0 1 0>,
				<DCC_READ 0x196c04b0 1 0>,
				<DCC_READ 0x196c04b4 1 0>,
				<DCC_READ 0x196c04b8 1 0>,
				<DCC_READ 0x196c04d0 1 0>,
				<DCC_READ 0x196c04d4 1 0>,
				<DCC_READ 0x196c341c 1 0>,
				<DCC_READ 0x196c5804 1 0>,
				<DCC_READ 0x196c590c 1 0>,
				<DCC_READ 0x196c5a14 1 0>,
				<DCC_READ 0x196c5c1c 1 0>,
				<DCC_READ 0x196c5c38 1 0>,
				<DCC_READ 0x196c9100 1 0>,
				<DCC_READ 0x196c9110 1 0>,
				<DCC_READ 0x196c9120 1 0>,
				<DCC_READ 0x196c9180 1 0>,
				<DCC_READ 0x196c9184 1 0>,
				<DCC_READ 0x197c0310 1 0>,
				<DCC_READ 0x197c0400 1 0>,
				<DCC_READ 0x197c0404 1 0>,
				<DCC_READ 0x197c0410 1 0>,
				<DCC_READ 0x197c0414 1 0>,
				<DCC_READ 0x197c0418 1 0>,
				<DCC_READ 0x197c0420 1 0>,
				<DCC_READ 0x197c0424 1 0>,
				<DCC_READ 0x197c0430 1 0>,
				<DCC_READ 0x197c0440 1 0>,
				<DCC_READ 0x197c0448 1 0>,
				<DCC_READ 0x197c04a0 1 0>,
				<DCC_READ 0x197c04b0 1 0>,
				<DCC_READ 0x197c04b4 1 0>,
				<DCC_READ 0x197c04b8 1 0>,
				<DCC_READ 0x197c04d0 1 0>,
				<DCC_READ 0x197c04d4 1 0>,
				<DCC_READ 0x197c341c 1 0>,
				<DCC_READ 0x197c5804 1 0>,
				<DCC_READ 0x197c590c 1 0>,
				<DCC_READ 0x197c5a14 1 0>,
				<DCC_READ 0x197c5c1c 1 0>,
				<DCC_READ 0x197c5c38 1 0>,
				<DCC_READ 0x197c9100 1 0>,
				<DCC_READ 0x197c9110 1 0>,
				<DCC_READ 0x197c9120 1 0>,
				<DCC_READ 0x197c9180 1 0>,
				<DCC_READ 0x197c9184 1 0>,
				<DCC_READ 0x192c5cac 1 0>,
				<DCC_READ 0x192c5cb0 1 0>,
				<DCC_READ 0x192c5cb4 1 0>,
				<DCC_READ 0x196c5cac 1 0>,
				<DCC_READ 0x196c5cb0 1 0>,
				<DCC_READ 0x196c5cb4 1 0>,
				<DCC_READ 0x193c5cac 1 0>,
				<DCC_READ 0x193c5cb0 1 0>,
				<DCC_READ 0x193c5cb4 1 0>,
				<DCC_READ 0x197c5cac 1 0>,
				<DCC_READ 0x197c5cb0 1 0>,
				<DCC_READ 0x197c5cb4 1 0>,
				<DCC_READ 0x190ba28c 1 0>,
				<DCC_READ 0x190ba294 1 0>,
				<DCC_READ 0x190ba29c 1 0>,
				<DCC_READ 0x192e0618 1 0>,
				<DCC_READ 0x192e0684 1 0>,
				<DCC_READ 0x192e068c 1 0>,
				<DCC_READ 0x193e0618 1 0>,
				<DCC_READ 0x193e0684 1 0>,
				<DCC_READ 0x193e068c 1 0>,
				<DCC_READ 0x196e0618 1 0>,
				<DCC_READ 0x196e0684 1 0>,
				<DCC_READ 0x196e068c 1 0>,
				<DCC_READ 0x197e0618 1 0>,
				<DCC_READ 0x197e0684 1 0>,
				<DCC_READ 0x197e068c 1 0>,
				<DCC_READ 0x19281e64 1 0>,
				<DCC_READ 0x19281ea0 1 0>,
				<DCC_READ 0x19283e64 1 0>,
				<DCC_READ 0x19283ea0 1 0>,
				<DCC_READ 0x1928527c 1 0>,
				<DCC_READ 0x19285290 1 0>,
				<DCC_READ 0x192854ec 1 0>,
				<DCC_READ 0x192854f4 1 0>,
				<DCC_READ 0x19285514 1 0>,
				<DCC_READ 0x1928551c 1 0>,
				<DCC_READ 0x19285524 1 0>,
				<DCC_READ 0x19285548 1 0>,
				<DCC_READ 0x19285550 1 0>,
				<DCC_READ 0x19285558 1 0>,
				<DCC_READ 0x192855b8 1 0>,
				<DCC_READ 0x192855c0 1 0>,
				<DCC_READ 0x192855ec 1 0>,
				<DCC_READ 0x19285870 1 0>,
				<DCC_READ 0x192858a0 1 0>,
				<DCC_READ 0x192858a8 1 0>,
				<DCC_READ 0x192858b0 1 0>,
				<DCC_READ 0x192858b8 1 0>,
				<DCC_READ 0x192858d8 1 0>,
				<DCC_READ 0x192858dc 1 0>,
				<DCC_READ 0x192858f4 1 0>,
				<DCC_READ 0x192858fc 1 0>,
				<DCC_READ 0x19285920 1 0>,
				<DCC_READ 0x19285928 1 0>,
				<DCC_READ 0x19285944 1 0>,
				<DCC_READ 0x19286314 1 0>,
				<DCC_READ 0x19286454 1 0>,
				<DCC_READ 0x19286594 1 0>,
				<DCC_READ 0x19286604 1 0>,
				<DCC_READ 0x1928660c 1 0>,
				<DCC_READ 0x19381e64 1 0>,
				<DCC_READ 0x19381ea0 1 0>,
				<DCC_READ 0x19383e64 1 0>,
				<DCC_READ 0x19383ea0 1 0>,
				<DCC_READ 0x1938527c 1 0>,
				<DCC_READ 0x19385290 1 0>,
				<DCC_READ 0x193854ec 1 0>,
				<DCC_READ 0x193854f4 1 0>,
				<DCC_READ 0x19385514 1 0>,
				<DCC_READ 0x1938551c 1 0>,
				<DCC_READ 0x19385524 1 0>,
				<DCC_READ 0x19385548 1 0>,
				<DCC_READ 0x19385550 1 0>,
				<DCC_READ 0x19385558 1 0>,
				<DCC_READ 0x193855b8 1 0>,
				<DCC_READ 0x193855c0 1 0>,
				<DCC_READ 0x193855ec 1 0>,
				<DCC_READ 0x19385870 1 0>,
				<DCC_READ 0x193858a0 1 0>,
				<DCC_READ 0x193858a8 1 0>,
				<DCC_READ 0x193858b0 1 0>,
				<DCC_READ 0x193858b8 1 0>,
				<DCC_READ 0x193858d8 1 0>,
				<DCC_READ 0x193858dc 1 0>,
				<DCC_READ 0x193858f4 1 0>,
				<DCC_READ 0x193858fc 1 0>,
				<DCC_READ 0x19385920 1 0>,
				<DCC_READ 0x19385928 1 0>,
				<DCC_READ 0x19385944 1 0>,
				<DCC_READ 0x19386314 1 0>,
				<DCC_READ 0x19386454 1 0>,
				<DCC_READ 0x19386594 1 0>,
				<DCC_READ 0x19386604 1 0>,
				<DCC_READ 0x1938660c 1 0>,
				<DCC_READ 0x19681e64 1 0>,
				<DCC_READ 0x19681ea0 1 0>,
				<DCC_READ 0x19683e64 1 0>,
				<DCC_READ 0x19683ea0 1 0>,
				<DCC_READ 0x1968527c 1 0>,
				<DCC_READ 0x19685290 1 0>,
				<DCC_READ 0x196854ec 1 0>,
				<DCC_READ 0x196854f4 1 0>,
				<DCC_READ 0x19685514 1 0>,
				<DCC_READ 0x1968551c 1 0>,
				<DCC_READ 0x19685524 1 0>,
				<DCC_READ 0x19685548 1 0>,
				<DCC_READ 0x19685550 1 0>,
				<DCC_READ 0x19685558 1 0>,
				<DCC_READ 0x196855b8 1 0>,
				<DCC_READ 0x196855c0 1 0>,
				<DCC_READ 0x196855ec 1 0>,
				<DCC_READ 0x19685870 1 0>,
				<DCC_READ 0x196858a0 1 0>,
				<DCC_READ 0x196858a8 1 0>,
				<DCC_READ 0x196858b0 1 0>,
				<DCC_READ 0x196858b8 1 0>,
				<DCC_READ 0x196858d8 1 0>,
				<DCC_READ 0x196858dc 1 0>,
				<DCC_READ 0x196858f4 1 0>,
				<DCC_READ 0x196858fc 1 0>,
				<DCC_READ 0x19685920 1 0>,
				<DCC_READ 0x19685928 1 0>,
				<DCC_READ 0x19685944 1 0>,
				<DCC_READ 0x19686314 1 0>,
				<DCC_READ 0x19686454 1 0>,
				<DCC_READ 0x19686594 1 0>,
				<DCC_READ 0x19686604 1 0>,
				<DCC_READ 0x1968660c 1 0>,
				<DCC_READ 0x19781e64 1 0>,
				<DCC_READ 0x19781ea0 1 0>,
				<DCC_READ 0x19783e64 1 0>,
				<DCC_READ 0x19783ea0 1 0>,
				<DCC_READ 0x1978527c 1 0>,
				<DCC_READ 0x19785290 1 0>,
				<DCC_READ 0x197854ec 1 0>,
				<DCC_READ 0x197854f4 1 0>,
				<DCC_READ 0x19785514 1 0>,
				<DCC_READ 0x1978551c 1 0>,
				<DCC_READ 0x19785524 1 0>,
				<DCC_READ 0x19785548 1 0>,
				<DCC_READ 0x19785550 1 0>,
				<DCC_READ 0x19785558 1 0>,
				<DCC_READ 0x197855b8 1 0>,
				<DCC_READ 0x197855c0 1 0>,
				<DCC_READ 0x197855ec 1 0>,
				<DCC_READ 0x19785870 1 0>,
				<DCC_READ 0x197858a0 1 0>,
				<DCC_READ 0x197858a8 1 0>,
				<DCC_READ 0x197858b0 1 0>,
				<DCC_READ 0x197858b8 1 0>,
				<DCC_READ 0x197858d8 1 0>,
				<DCC_READ 0x197858dc 1 0>,
				<DCC_READ 0x197858f4 1 0>,
				<DCC_READ 0x197858fc 1 0>,
				<DCC_READ 0x19785920 1 0>,
				<DCC_READ 0x19785928 1 0>,
				<DCC_READ 0x19785944 1 0>,
				<DCC_READ 0x19786314 1 0>,
				<DCC_READ 0x19786454 1 0>,
				<DCC_READ 0x19786594 1 0>,
				<DCC_READ 0x19786604 1 0>,
				<DCC_READ 0x1978660c 1 0>,
				<DCC_READ 0x610110 1 0>,
				<DCC_READ 0x610114 1 0>,
				<DCC_READ 0x610118 1 0>,
				<DCC_READ 0x61011c 1 0>,
				<DCC_READ 0x610120 1 0>,
				<DCC_READ 0x1908e01c 1 0>,
				<DCC_READ 0x1908e030 1 0>,
				<DCC_READ 0x19032020 1 0>,
				<DCC_READ 0x19032024 1 0>,
				<DCC_WRITE 0x19030040 0x1 1>,
				<DCC_WRITE 0x1903005c 0x22c000 1>,
				<DCC_READ 0x19030010 1 0>,
				<DCC_WRITE 0x1903005c 0x22c001 1>,
				<DCC_READ 0x19030010 1 0>,
				<DCC_WRITE 0x1903005c 0x22c002 1>,
				<DCC_READ 0x19030010 1 0>,
				<DCC_WRITE 0x1903005c 0x22c003 1>,
				<DCC_READ 0x19030010 1 0>,
				<DCC_WRITE 0x1903005c 0x22c004 1>,
				<DCC_READ 0x19030010 1 0>,
				<DCC_WRITE 0x1903005c 0x22c005 1>,
				<DCC_READ 0x19030010 1 0>,
				<DCC_WRITE 0x1903005c 0x22c006 1>,
				<DCC_READ 0x19030010 1 0>,
				<DCC_WRITE 0x1903005c 0x22c007 1>,
				<DCC_READ 0x19030010 1 0>,
				<DCC_WRITE 0x1903005c 0x22c008 1>,
				<DCC_READ 0x19030010 1 0>,
				<DCC_WRITE 0x1903005c 0x22c009 1>,
				<DCC_READ 0x19030010 1 0>,
				<DCC_WRITE 0x1903005c 0x22c00a 1>,
				<DCC_READ 0x19030010 1 0>,
				<DCC_WRITE 0x1903005c 0x22c00b 1>,
				<DCC_READ 0x19030010 1 0>,
				<DCC_WRITE 0x1903005c 0x22c00c 1>,
				<DCC_READ 0x19030010 1 0>,
				<DCC_WRITE 0x1903005c 0x22c00d 1>,
				<DCC_READ 0x19030010 1 0>,
				<DCC_WRITE 0x1903005c 0x22c00e 1>,
				<DCC_READ 0x19030010 1 0>,
				<DCC_WRITE 0x1903005c 0x22c00f 1>,
				<DCC_READ 0x19030010 1 0>,
				<DCC_WRITE 0x1903005c 0x22c010 1>,
				<DCC_READ 0x19030010 1 0>,
				<DCC_WRITE 0x1903005c 0x22c011 1>,
				<DCC_READ 0x19030010 1 0>,
				<DCC_WRITE 0x1903005c 0x22c012 1>,
				<DCC_READ 0x19030010 1 0>,
				<DCC_WRITE 0x1903005c 0x22c013 1>,
				<DCC_READ 0x19030010 1 0>,
				<DCC_WRITE 0x1903005c 0x22c014 1>,
				<DCC_READ 0x19030010 1 0>,
				<DCC_WRITE 0x1903005c 0x22c015 1>,
				<DCC_READ 0x19030010 1 0>,
				<DCC_WRITE 0x1903005c 0x22c016 1>,
				<DCC_READ 0x19030010 1 0>,
				<DCC_WRITE 0x1903005c 0x22c017 1>,
				<DCC_READ 0x19030010 1 0>,
				<DCC_WRITE 0x1903005c 0x22c018 1>,
				<DCC_READ 0x19030010 1 0>,
				<DCC_WRITE 0x1903005c 0x22c019 1>,
				<DCC_READ 0x19030010 1 0>,
				<DCC_WRITE 0x1903005c 0x22c01a 1>,
				<DCC_READ 0x19030010 1 0>,
				<DCC_WRITE 0x1903005c 0x22c01b 1>,
				<DCC_READ 0x19030010 1 0>,
				<DCC_WRITE 0x1903005c 0x22c01c 1>,
				<DCC_READ 0x19030010 1 0>,
				<DCC_WRITE 0x1903005c 0x22c01d 1>,
				<DCC_READ 0x19030010 1 0>,
				<DCC_WRITE 0x1903005c 0x22c01e 1>,
				<DCC_READ 0x19030010 1 0>,
				<DCC_WRITE 0x1903005c 0x22c01f 1>,
				<DCC_READ 0x19030010 1 0>,
				<DCC_WRITE 0x1903005c 0x22c300 1>,
				<DCC_READ 0x19030010 1 0>,
				<DCC_WRITE 0x1903005c 0x22c341 1>,
				<DCC_READ 0x19030010 1 0>,
				<DCC_WRITE 0x1903005c 0x22c7b1 1>,
				<DCC_READ 0x19030010 1 0>,
				<DCC_READ 0x32302028 1 0>,
				<DCC_READ 0x320a4404 1 0>,
				<DCC_READ 0x320a4408 1 0>,
				<DCC_READ 0x323b0404 1 0>,
				<DCC_READ 0x323b0408 1 0>,
				<DCC_READ 0xb2b1020 1 0>,
				<DCC_READ 0xb2b1024 1 0>;
		};

		link_list_1 {
			qcom,curr-link-list = <4>;
			qcom,data-sink = "sram";
			qcom,link-list = <DCC_READ 0x190e0010 1 0>,
				<DCC_READ 0x190e0020 8 0>,
				<DCC_READ 0x190e0248 1 0>,
				<DCC_READ 0x195f0010 1 0>,
				<DCC_READ 0x195f0020 8 0>,
				<DCC_READ 0x195f0248 1 0>,
				<DCC_READ 0x199f0010 1 0>,
				<DCC_READ 0x199f0020 8 0>,
				<DCC_READ 0x199f0248 1 0>,
				<DCC_READ 0x190e5018 1 0>,
				<DCC_READ 0x190e5008 1 0>,
				<DCC_LOOP 0x6  0 0>,
				<DCC_READ 0x190e5010 2 0>,
				<DCC_LOOP 0x1 0 0>,
				<DCC_READ 0x195f2018 1 0>,
				<DCC_READ 0x195f2008 1 0>,
				<DCC_LOOP 0x3  0 0>,
				<DCC_READ 0x195f2010 2 0>,
				<DCC_LOOP 0x1 0 0>,
				<DCC_READ 0x199f2018 1 0>,
				<DCC_READ 0x199f2008 1 0>,
				<DCC_LOOP 0x3  0 0>,
				<DCC_READ 0x199f2010 2 0>,
				<DCC_LOOP 0x1 0 0>,
				<DCC_READ 0x3c40010 1 0>,
				<DCC_READ 0x3c40020 8 0>,
				<DCC_READ 0x3c4b048 1 0>,
				<DCC_READ 0x3c41018 1 0>,
				<DCC_READ 0x3c41008 1 0>,
				<DCC_LOOP 0x5  0 0>,
				<DCC_READ 0x3c41010 2 0>,
				<DCC_LOOP 0x1 0 0>,
				<DCC_READ 0x1740008 1 0>,
				<DCC_READ 0x1740020 8 0>,
				<DCC_READ 0x174c048 1 0>,
				<DCC_READ 0x1741018 1 0>,
				<DCC_READ 0x1741008 1 0>,
				<DCC_LOOP 0xb  0 0>,
				<DCC_READ 0x1741010 2 0>,
				<DCC_LOOP 0x1 0 0>,
				<DCC_READ 0x1680010 1 0>,
				<DCC_READ 0x1680020 8 0>,
				<DCC_READ 0x1681048 1 0>,
				<DCC_READ 0x1682018 1 0>,
				<DCC_READ 0x1682008 1 0>,
				<DCC_LOOP 0x7  0 0>,
				<DCC_READ 0x1682010 2 0>,
				<DCC_LOOP 0x1 0 0>,
				<DCC_READ 0x16e0010 1 0>,
				<DCC_READ 0x16e0020 8 0>,
				<DCC_READ 0x16e8048 1 0>,
				<DCC_READ 0x1700010 1 0>,
				<DCC_READ 0x1700020 8 0>,
				<DCC_READ 0x1708048 1 0>,
				<DCC_READ 0x16c0010 1 0>,
				<DCC_READ 0x16c0020 8 0>,
				<DCC_READ 0x16cc048 1 0>,
				<DCC_READ 0x16e6018 1 0>,
				<DCC_READ 0x16e6008 1 0>,
				<DCC_LOOP 0x4  0 0>,
				<DCC_READ 0x16e6010 2 0>,
				<DCC_LOOP 0x1 0 0>,
				<DCC_READ 0x16c2018 1 0>,
				<DCC_READ 0x16c2008 1 0>,
				<DCC_LOOP 0x4  0 0>,
				<DCC_READ 0x16c2010 2 0>,
				<DCC_LOOP 0x1 0 0>,
				<DCC_READ 0x1706118 1 0>,
				<DCC_READ 0x1706108 1 0>,
				<DCC_LOOP 0x3  0 0>,
				<DCC_READ 0x1706110 2 0>,
				<DCC_LOOP 0x1 0 0>,
				<DCC_READ 0x1706098 1 0>,
				<DCC_READ 0x1706088 1 0>,
				<DCC_LOOP 0x3  0 0>,
				<DCC_READ 0x1706090 2 0>,
				<DCC_LOOP 0x1 0 0>,
				<DCC_READ 0x1706018 1 0>,
				<DCC_READ 0x1706008 1 0>,
				<DCC_LOOP 0x5  0 0>,
				<DCC_READ 0x1706010 2 0>,
				<DCC_LOOP 0x1 0 0>,
				<DCC_READ 0x1500010 1 0>,
				<DCC_READ 0x1500020 8 0>,
				<DCC_READ 0x1500248 2 0>,
				<DCC_READ 0x1500258 1 0>,
				<DCC_READ 0x1500448 1 0>,
				<DCC_READ 0x1510098 1 0>,
				<DCC_READ 0x1510088 1 0>,
				<DCC_LOOP 0x2  0 0>,
				<DCC_READ 0x1510090 2 0>,
				<DCC_LOOP 0x1 0 0>,
				<DCC_READ 0x1513018 1 0>,
				<DCC_READ 0x1513008 1 0>,
				<DCC_LOOP 0x3  0 0>,
				<DCC_READ 0x1513010 2 0>,
				<DCC_LOOP 0x1 0 0>,
				<DCC_READ 0x1512018 1 0>,
				<DCC_READ 0x1512008 1 0>,
				<DCC_LOOP 0x4  0 0>,
				<DCC_READ 0x1512010 2 0>,
				<DCC_LOOP 0x1 0 0>,
				<DCC_READ 0x1511018 1 0>,
				<DCC_READ 0x1511008 1 0>,
				<DCC_LOOP 0x2  0 0>,
				<DCC_READ 0x1511010 2 0>,
				<DCC_LOOP 0x1 0 0>,
				<DCC_READ 0x1514018 1 0>,
				<DCC_READ 0x1514008 1 0>,
				<DCC_LOOP 0x3  0 0>,
				<DCC_READ 0x1514010 2 0>,
				<DCC_LOOP 0x1 0 0>,
				<DCC_READ 0x1510018 1 0>,
				<DCC_READ 0x1510008 1 0>,
				<DCC_LOOP 0xb  0 0>,
				<DCC_READ 0x1510010 2 0>,
				<DCC_LOOP 0x1 0 0>,
				<DCC_READ 0x17100104 29 0>,
				<DCC_READ 0x17100204 29 0>,
				<DCC_READ 0x17100384 29 0>,
				<DCC_READ 0xb281024 1 0>,
				<DCC_READ 0xbde1034 1 0>,
				<DCC_READ 0xb201020 2 0>,
				<DCC_READ 0xb211020 2 0>,
				<DCC_READ 0xb221020 2 0>,
				<DCC_READ 0xb231020 2 0>,
				<DCC_READ 0xb204520 1 0>,
				<DCC_READ 0x17a00010 1 0>,
				<DCC_READ 0x17a10010 1 0>,
				<DCC_READ 0x17a20010 1 0>,
				<DCC_READ 0x17a30010 1 0>,
				<DCC_READ 0x17a00030 1 0>,
				<DCC_READ 0x17a10030 1 0>,
				<DCC_READ 0x17a20030 1 0>,
				<DCC_READ 0x17a30030 1 0>,
				<DCC_READ 0x17a00038 1 0>,
				<DCC_READ 0x17a10038 1 0>,
				<DCC_READ 0x17a20038 1 0>,
				<DCC_READ 0x17a30038 1 0>,
				<DCC_READ 0x17a00040 1 0>,
				<DCC_READ 0x17a10040 1 0>,
				<DCC_READ 0x17a20040 1 0>,
				<DCC_READ 0x17a30040 1 0>,
				<DCC_READ 0x17a00048 1 0>,
				<DCC_READ 0x17a00400 3 0>,
				<DCC_READ 0x17a10400 3 0>,
				<DCC_READ 0x17a20400 3 0>,
				<DCC_READ 0x17a30400 3 0>,
				<DCC_READ 0xc230000 6 0>;
		};
	};

	mem_dump {
		compatible = "qcom,mem-dump";
		memory-region = <&dump_mem>;

		c0_context {
			qcom,dump-size = <0x800>;
			qcom,dump-id = <0x0>;
		};

		c100_context {
			qcom,dump-size = <0x800>;
			qcom,dump-id = <0x1>;
		};

		c200_context {
			qcom,dump-size = <0x800>;
			qcom,dump-id = <0x2>;
		};

		c300_context {
			qcom,dump-size = <0x800>;
			qcom,dump-id = <0x3>;
		};

		c400_context {
			qcom,dump-size = <0x800>;
			qcom,dump-id = <0x4>;
		};

		c500_context {
			qcom,dump-size = <0x800>;
			qcom,dump-id = <0x5>;
		};

		c600_context {
			qcom,dump-size = <0x800>;
			qcom,dump-id = <0x6>;
		};

		c700_context {
			qcom,dump-size = <0x800>;
			qcom,dump-id = <0x7>;
		};

		complex0_scan {
			qcom,dump-size = <0x4a100>;
			qcom,dump-id = <0x130>;
		};

		complex1_scan {
			qcom,dump-size = <0x4a100>;
			qcom,dump-id = <0x131>;
		};

		gold0_scan {
			qcom,dump-size = <0x5f700>;
			qcom,dump-id = <0x132>;
		};

		gold1_scan {
			qcom,dump-size = <0x5f700>;
			qcom,dump-id = <0x133>;
		};

		gold2_scan {
			qcom,dump-size = <0x5f700>;
			qcom,dump-id = <0x134>;
		};

		gold3_scan {
			qcom,dump-size = <0x81100>;
			qcom,dump-id = <0x135>;
		};

		l3slice0scan {
			qcom,dump-size = <0x4cd00>;
			qcom,dump-id = <0x136>;
		};

		l3slice1scan {
			qcom,dump-size = <0x14e00>;
			qcom,dump-id = <0x137>;
		};

		l3slice2scan {
			qcom,dump-size = <0x14e00>;
			qcom,dump-id = <0x138>;
		};

		l3slice3scan {
			qcom,dump-size = <0x14e00>;
			qcom,dump-id = <0x139>;
		};

		mhm_scan {
			qcom,dump-size = <0x5a700>;
			qcom,dump-id = <0x161>;
		};

		l1_icache0 {
			qcom,dump-size = <0x9100>;
			qcom,dump-id = <0x60>;
		};

		l1_icache100 {
			qcom,dump-size = <0x9100>;
			qcom,dump-id = <0x61>;
		};

		l1_icache200 {
			qcom,dump-size = <0x9100>;
			qcom,dump-id = <0x62>;
		};

		l1_icache300 {
			qcom,dump-size = <0x9100>;
			qcom,dump-id = <0x63>;
		};

		l1_icache400 {
			qcom,dump-size = <0x11100>;
			qcom,dump-id = <0x64>;
		};

		l1_icache500 {
			qcom,dump-size = <0x11100>;
			qcom,dump-id = <0x65>;
		};

		l1_icache600 {
			qcom,dump-size = <0x11100>;
			qcom,dump-id = <0x66>;
		};

		l1_icache700 {
			qcom,dump-size = <0x22100>;
			qcom,dump-id = <0x67>;
		};

		l1_dcache0 {
			qcom,dump-size = <0x9100>;
			qcom,dump-id = <0x80>;
		};

		l1_dcache100 {
			qcom,dump-size = <0x9100>;
			qcom,dump-id = <0x81>;
		};

		l1_dcache200 {
			qcom,dump-size = <0x9100>;
			qcom,dump-id = <0x82>;
		};

		l1_dcache300 {
			qcom,dump-size = <0x9100>;
			qcom,dump-id = <0x83>;
		};

		l1_dcache400 {
			qcom,dump-size = <0xd100>;
			qcom,dump-id = <0x84>;
		};

		l1_dcache500 {
			qcom,dump-size = <0xd100>;
			qcom,dump-id = <0x85>;
		};

		l1_dcache600 {
			qcom,dump-size = <0xd100>;
			qcom,dump-id = <0x86>;
		};

		l1_dcache700 {
			qcom,dump-size = <0x1a100>;
			qcom,dump-id = <0x87>;
		};

		l1_itlb400 {
			qcom,dump-size = <0x600>;
			qcom,dump-id = <0x24>;
		};

		l1_itlb500 {
			qcom,dump-size = <0x600>;
			qcom,dump-id = <0x25>;
		};

		l1_itlb600 {
			qcom,dump-size = <0x600>;
			qcom,dump-id = <0x26>;
		};

		l1_itlb700 {
			qcom,dump-size = <0x600>;
			qcom,dump-id = <0x27>;
		};

		l1_dtlb400 {
			qcom,dump-size = <0x600>;
			qcom,dump-id = <0x44>;
		};

		l1_dtlb500 {
			qcom,dump-size = <0x600>;
			qcom,dump-id = <0x45>;
		};

		l1_dtlb600 {
			qcom,dump-size = <0x600>;
			qcom,dump-id = <0x46>;
		};

		l1_dtlb700 {
			qcom,dump-size = <0x600>;
			qcom,dump-id = <0x47>;
		};

		l2_cache0 {
			qcom,dump-size = <0x14100>;
			qcom,dump-id = <0xc0>;
		};

		l2_cache100 {
			qcom,dump-size = <0x14100>;
			qcom,dump-id = <0xc1>;
		};

		l2_cache200 {
			qcom,dump-size = <0x14100>;
			qcom,dump-id = <0xc2>;
		};

		l2_cache300 {
			qcom,dump-size = <0x14100>;
			qcom,dump-id = <0xc3>;
		};

		l2_cache400 {
			qcom,dump-size = <0xd0100>;
			qcom,dump-id = <0xc4>;
		};

		l2_cache500 {
			qcom,dump-size = <0xd0100>;
			qcom,dump-id = <0xc5>;
		};

		l2_cache600 {
			qcom,dump-size = <0xd0100>;
			qcom,dump-id = <0xc6>;
		};

		l2_cache700 {
			qcom,dump-size = <0x1a0100>;
			qcom,dump-id = <0xc7>;
		};

		l2_tlb0 {
			qcom,dump-size = <0x2100>;
			qcom,dump-id = <0x120>;
		};

		l2_tlb100 {
			qcom,dump-size = <0x2100>;
			qcom,dump-id = <0x121>;
		};

		l2_tlb200 {
			qcom,dump-size = <0x2100>;
			qcom,dump-id = <0x122>;
		};

		l2_tlb300 {
			qcom,dump-size = <0x2100>;
			qcom,dump-id = <0x123>;
		};

		l2_tlb400 {
			qcom,dump-size = <0xc100>;
			qcom,dump-id = <0x124>;
		};

		l2_tlb500 {
			qcom,dump-size = <0xc100>;
			qcom,dump-id = <0x125>;
		};

		l2_tlb600 {
			qcom,dump-size = <0xc100>;
			qcom,dump-id = <0x126>;
		};

		l2_tlb700 {
			qcom,dump-size = <0xc100>;
			qcom,dump-id = <0x127>;
		};

		l1dcdirty0 {
			qcom,dump-size = <0x1100>;
			qcom,dump-id = <0x170>;
		};

		l1dcdirty100 {
			qcom,dump-size = <0x1100>;
			qcom,dump-id = <0x171>;
		};

		l1dcdirty200 {
			qcom,dump-size = <0x1100>;
			qcom,dump-id = <0x172>;
		};

		l1dcdirty300 {
			qcom,dump-size = <0x1100>;
			qcom,dump-id = <0x173>;
		};

		l1dcmte0 {
			qcom,dump-size = <0x1100>;
			qcom,dump-id = <0x180>;
		};

		l1dcmte100 {
			qcom,dump-size = <0x1100>;
			qcom,dump-id = <0x181>;
		};

		l1dcmte200 {
			qcom,dump-size = <0x1100>;
			qcom,dump-id = <0x182>;
		};

		l1dcmte300 {
			qcom,dump-size = <0x1100>;
			qcom,dump-id = <0x183>;
		};

		l2dcmte0 {
			qcom,dump-size = <0x4100>;
			qcom,dump-id = <0x190>;
		};

		l2dcmte100 {
			qcom,dump-size = <0x4100>;
			qcom,dump-id = <0x191>;
		};

		l2dcmte200 {
			qcom,dump-size = <0x4100>;
			qcom,dump-id = <0x192>;
		};

		l2dcmte300 {
			qcom,dump-size = <0x4100>;
			qcom,dump-id = <0x193>;
		};

		l0mopca400 {
			qcom,dump-size = <0x6100>;
			qcom,dump-id = <0x1a4>;
		};

		l0mopca500 {
			qcom,dump-size = <0x6100>;
			qcom,dump-id = <0x1a5>;
		};

		l0mopca600 {
			qcom,dump-size = <0x6100>;
			qcom,dump-id = <0x1a6>;
		};

		l0mopca700 {
			qcom,dump-size = <0xc100>;
			qcom,dump-id = <0x1a7>;
		};

		l1btb400 {
			qcom,dump-size = <0x10100>;
			qcom,dump-id = <0x1b4>;
		};

		l1btb500 {
			qcom,dump-size = <0x10100>;
			qcom,dump-id = <0x1b5>;
		};

		l1btb600 {
			qcom,dump-size = <0x10100>;
			qcom,dump-id = <0x1b6>;
		};

		l1btb700 {
			qcom,dump-size = <0x10100>;
			qcom,dump-id = <0x1b7>;
		};

		l1ghb400 {
			qcom,dump-size = <0x4100>;
			qcom,dump-id = <0x1c4>;
		};

		l1ghb500 {
			qcom,dump-size = <0x4100>;
			qcom,dump-id = <0x1c5>;
		};

		l1ghb600 {
			qcom,dump-size = <0x4100>;
			qcom,dump-id = <0x1c6>;
		};

		l1ghb700 {
			qcom,dump-size = <0x8100>;
			qcom,dump-id = <0x1c7>;
		};

		l1bim400 {
			qcom,dump-size = <0x2100>;
			qcom,dump-id = <0x1d4>;
		};

		l1bim500 {
			qcom,dump-size = <0x2100>;
			qcom,dump-id = <0x1d5>;
		};

		l1bim600 {
			qcom,dump-size = <0x2100>;
			qcom,dump-id = <0x1d6>;
		};

		l1bim700 {
			qcom,dump-size = <0x4100>;
			qcom,dump-id = <0x1d7>;
		};

		l2victim400 {
			qcom,dump-size = <0x2100>;
			qcom,dump-id = <0x1e4>;
		};

		l2victim500 {
			qcom,dump-size = <0x2100>;
			qcom,dump-id = <0x1e5>;
		};

		l2victim600 {
			qcom,dump-size = <0x2100>;
			qcom,dump-id = <0x1e6>;
		};

		l2victim700 {
			qcom,dump-size = <0x2100>;
			qcom,dump-id = <0x1e7>;
		};

		cpuss_reg {
			qcom,dump-size = <0x30000>;
			qcom,dump-id = <0xef>;
		};

		gemnoc {
			qcom,dump-size = <0x100000>;
			qcom,dump-id = <0x162>;
		};

		rpmh {
			qcom,dump-size = <0x2000000>;
			qcom,dump-id = <0xec>;
		};

		rpm_sw {
			qcom,dump-size = <0x28000>;
			qcom,dump-id = <0xea>;
		};

		pmic {
			qcom,dump-size = <0x200000>;
			qcom,dump-id = <0xe4>;
		};

		fcm {
			qcom,dump-size = <0x8400>;
			qcom,dump-id = <0xee>;
		};

		etf_swao {
			qcom,dump-size = <0x10000>;
			qcom,dump-id = <0xf1>;
		};

		etr_reg {
			qcom,dump-size = <0x1000>;
			qcom,dump-id = <0x100>;
		};

		etfswao_reg {
			qcom,dump-size = <0x1000>;
			qcom,dump-id = <0x102>;
		};

		etr1_reg {
			qcom,dump-size = <0x1000>;
			qcom,dump-id = <0x105>;
		};

		misc_data {
			qcom,dump-size = <0x1000>;
			qcom,dump-id = <0xe8>;
		};

		etf_slpi {
			qcom,dump-size = <0x4000>;
			qcom,dump-id = <0xf3>;
		};

		etfslpi_reg {
			qcom,dump-size = <0x1000>;
			qcom,dump-id = <0x103>;
		};

		etf_lpass {
			qcom,dump-size = <0x4000>;
			qcom,dump-id = <0xf4>;
		};

		etflpass_reg {
			qcom,dump-size = <0x1000>;
			qcom,dump-id = <0x104>;
		};

		llcc1dc {
			qcom,dump-size = <0x171000>;
			qcom,dump-id = <0x140>;
		};

		llcc2dc {
			qcom,dump-size = <0x171000>;
			qcom,dump-id = <0x141>;
		};

		llcc3dc {
			qcom,dump-size = <0x171000>;
			qcom,dump-id = <0x142>;
		};

		llcc4dc {
			qcom,dump-size = <0x171000>;
			qcom,dump-id = <0x143>;
		};
	};
};
